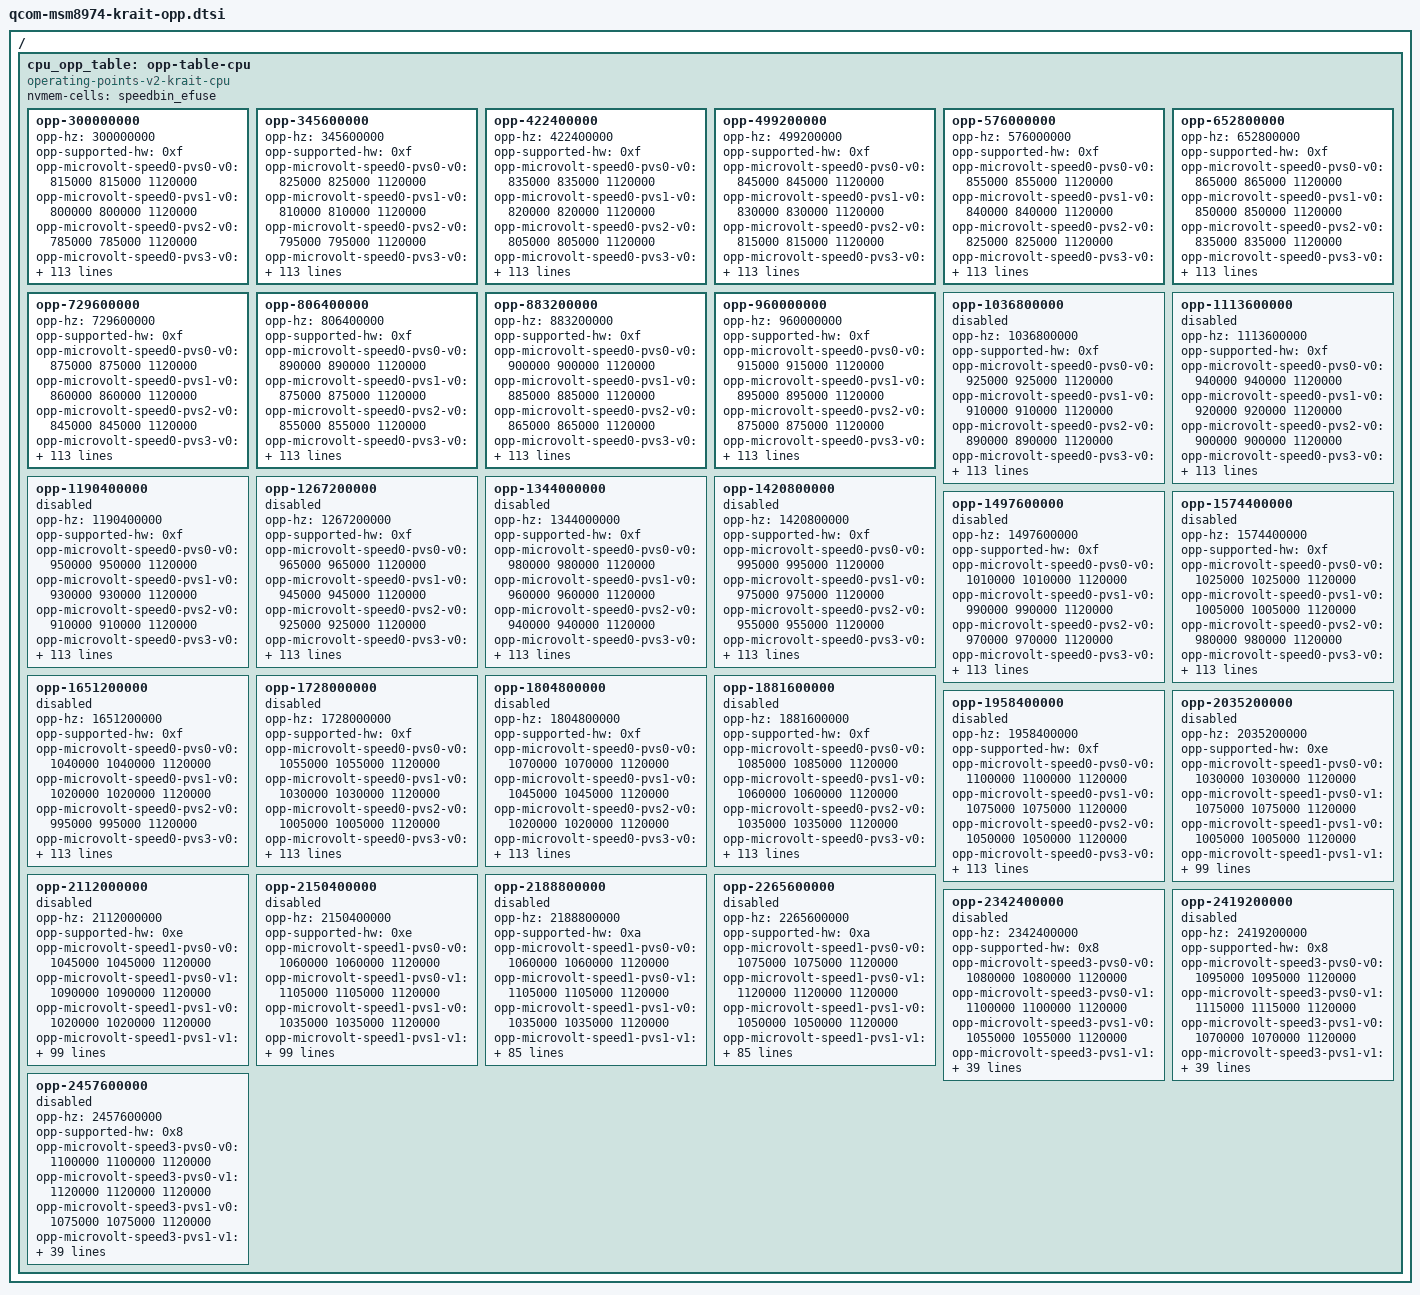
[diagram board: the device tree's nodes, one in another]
// SPDX-License-Identifier: GPL-2.0
/*
 * Krait CPU operating points for MSM8974.
 *
 * GENERATED by cpufreq/gen-krait-opp.py from Sony's stock device tree.
 * Do not edit by hand; regenerate with a different --cap-hz instead.
 *
 * Every OPP above the cap carries status = "disabled" because Linux has
 * no driver for the Krait per-core LDO/BHS regulator and so cannot raise
 * CPU voltage. See cpufreq/README.md.
 */

/ {
	cpu_opp_table: opp-table-cpu {
		compatible = "operating-points-v2-krait-cpu";
		nvmem-cells = <&speedbin_efuse>;

		opp-300000000 {
			opp-hz = /bits/ 64 <300000000>;
			opp-supported-hw = <0xf>;
			opp-microvolt-speed0-pvs0-v0 = <815000 815000 1120000>;
			opp-microvolt-speed0-pvs1-v0 = <800000 800000 1120000>;
			opp-microvolt-speed0-pvs2-v0 = <785000 785000 1120000>;
			opp-microvolt-speed0-pvs3-v0 = <775000 775000 1120000>;
			opp-microvolt-speed0-pvs4-v0 = <775000 775000 1120000>;
			opp-microvolt-speed0-pvs5-v0 = <750000 750000 1120000>;
			opp-microvolt-speed0-pvs6-v0 = <750000 750000 1120000>;
			opp-microvolt-speed1-pvs0-v0 = <775000 775000 1120000>;
			opp-microvolt-speed1-pvs0-v1 = <800000 800000 1120000>;
			opp-microvolt-speed1-pvs1-v0 = <775000 775000 1120000>;
			opp-microvolt-speed1-pvs1-v1 = <800000 800000 1120000>;
			opp-microvolt-speed1-pvs2-v0 = <750000 750000 1120000>;
			opp-microvolt-speed1-pvs2-v1 = <800000 800000 1120000>;
			opp-microvolt-speed1-pvs3-v0 = <750000 750000 1120000>;
			opp-microvolt-speed1-pvs3-v1 = <800000 800000 1120000>;
			opp-microvolt-speed1-pvs4-v0 = <750000 750000 1120000>;
			opp-microvolt-speed1-pvs4-v1 = <800000 800000 1120000>;
			opp-microvolt-speed1-pvs5-v0 = <725000 725000 1120000>;
			opp-microvolt-speed1-pvs5-v1 = <800000 800000 1120000>;
			opp-microvolt-speed1-pvs6-v0 = <725000 725000 1120000>;
			opp-microvolt-speed1-pvs6-v1 = <775000 775000 1120000>;
			opp-microvolt-speed1-pvs7-v1 = <775000 775000 1120000>;
			opp-microvolt-speed1-pvs8-v1 = <775000 775000 1120000>;
			opp-microvolt-speed1-pvs9-v1 = <775000 775000 1120000>;
			opp-microvolt-speed1-pvs10-v1 = <775000 775000 1120000>;
			opp-microvolt-speed1-pvs11-v1 = <775000 775000 1120000>;
			opp-microvolt-speed1-pvs12-v1 = <775000 775000 1120000>;
			opp-microvolt-speed1-pvs13-v1 = <775000 775000 1120000>;
			opp-microvolt-speed1-pvs14-v1 = <750000 750000 1120000>;
			opp-microvolt-speed1-pvs15-v1 = <750000 750000 1120000>;
			opp-microvolt-speed2-pvs0-v0 = <800000 800000 1120000>;
			opp-microvolt-speed2-pvs1-v0 = <800000 800000 1120000>;
			opp-microvolt-speed2-pvs2-v0 = <775000 775000 1120000>;
			opp-microvolt-speed2-pvs3-v0 = <775000 775000 1120000>;
			opp-microvolt-speed2-pvs4-v0 = <775000 775000 1120000>;
			opp-microvolt-speed2-pvs5-v0 = <750000 750000 1120000>;
			opp-microvolt-speed2-pvs6-v0 = <750000 750000 1120000>;
			opp-microvolt-speed3-pvs0-v0 = <800000 800000 1120000>;
			opp-microvolt-speed3-pvs0-v1 = <800000 800000 1120000>;
			opp-microvolt-speed3-pvs1-v0 = <800000 800000 1120000>;
			opp-microvolt-speed3-pvs1-v1 = <800000 800000 1120000>;
			opp-microvolt-speed3-pvs2-v0 = <775000 775000 1120000>;
			opp-microvolt-speed3-pvs2-v1 = <800000 800000 1120000>;
			opp-microvolt-speed3-pvs3-v0 = <775000 775000 1120000>;
			opp-microvolt-speed3-pvs3-v1 = <800000 800000 1120000>;
			opp-microvolt-speed3-pvs4-v0 = <775000 775000 1120000>;
			opp-microvolt-speed3-pvs4-v1 = <800000 800000 1120000>;
			opp-microvolt-speed3-pvs5-v0 = <750000 750000 1120000>;
			opp-microvolt-speed3-pvs5-v1 = <800000 800000 1120000>;
			opp-microvolt-speed3-pvs6-v0 = <750000 750000 1120000>;
			opp-microvolt-speed3-pvs6-v1 = <775000 775000 1120000>;
			opp-microvolt-speed3-pvs7-v1 = <775000 775000 1120000>;
			opp-microvolt-speed3-pvs8-v1 = <775000 775000 1120000>;
			opp-microvolt-speed3-pvs9-v1 = <775000 775000 1120000>;
			opp-microvolt-speed3-pvs10-v1 = <775000 775000 1120000>;
			opp-microvolt-speed3-pvs11-v1 = <775000 775000 1120000>;
			opp-microvolt-speed3-pvs12-v1 = <775000 775000 1120000>;
			opp-microvolt-speed3-pvs13-v1 = <775000 775000 1120000>;
			opp-microvolt-speed3-pvs14-v1 = <750000 750000 1120000>;
			opp-microvolt-speed3-pvs15-v1 = <750000 750000 1120000>;
		};

		opp-345600000 {
			opp-hz = /bits/ 64 <345600000>;
			opp-supported-hw = <0xf>;
			opp-microvolt-speed0-pvs0-v0 = <825000 825000 1120000>;
			opp-microvolt-speed0-pvs1-v0 = <810000 810000 1120000>;
			opp-microvolt-speed0-pvs2-v0 = <795000 795000 1120000>;
			opp-microvolt-speed0-pvs3-v0 = <780000 780000 1120000>;
			opp-microvolt-speed0-pvs4-v0 = <775000 775000 1120000>;
			opp-microvolt-speed0-pvs5-v0 = <760000 760000 1120000>;
			opp-microvolt-speed0-pvs6-v0 = <750000 750000 1120000>;
			opp-microvolt-speed1-pvs0-v0 = <775000 775000 1120000>;
			opp-microvolt-speed1-pvs0-v1 = <810000 810000 1120000>;
			opp-microvolt-speed1-pvs1-v0 = <775000 775000 1120000>;
			opp-microvolt-speed1-pvs1-v1 = <800000 800000 1120000>;
			opp-microvolt-speed1-pvs2-v0 = <750000 750000 1120000>;
			opp-microvolt-speed1-pvs2-v1 = <800000 800000 1120000>;
			opp-microvolt-speed1-pvs3-v0 = <750000 750000 1120000>;
			opp-microvolt-speed1-pvs3-v1 = <800000 800000 1120000>;
			opp-microvolt-speed1-pvs4-v0 = <750000 750000 1120000>;
			opp-microvolt-speed1-pvs4-v1 = <800000 800000 1120000>;
			opp-microvolt-speed1-pvs5-v0 = <725000 725000 1120000>;
			opp-microvolt-speed1-pvs5-v1 = <800000 800000 1120000>;
			opp-microvolt-speed1-pvs6-v0 = <725000 725000 1120000>;
			opp-microvolt-speed1-pvs6-v1 = <775000 775000 1120000>;
			opp-microvolt-speed1-pvs7-v1 = <775000 775000 1120000>;
			opp-microvolt-speed1-pvs8-v1 = <775000 775000 1120000>;
			opp-microvolt-speed1-pvs9-v1 = <775000 775000 1120000>;
			opp-microvolt-speed1-pvs10-v1 = <775000 775000 1120000>;
			opp-microvolt-speed1-pvs11-v1 = <775000 775000 1120000>;
			opp-microvolt-speed1-pvs12-v1 = <775000 775000 1120000>;
			opp-microvolt-speed1-pvs13-v1 = <775000 775000 1120000>;
			opp-microvolt-speed1-pvs14-v1 = <750000 750000 1120000>;
			opp-microvolt-speed1-pvs15-v1 = <750000 750000 1120000>;
			opp-microvolt-speed2-pvs0-v0 = <800000 800000 1120000>;
			opp-microvolt-speed2-pvs1-v0 = <800000 800000 1120000>;
			opp-microvolt-speed2-pvs2-v0 = <775000 775000 1120000>;
			opp-microvolt-speed2-pvs3-v0 = <775000 775000 1120000>;
			opp-microvolt-speed2-pvs4-v0 = <775000 775000 1120000>;
			opp-microvolt-speed2-pvs5-v0 = <750000 750000 1120000>;
			opp-microvolt-speed2-pvs6-v0 = <750000 750000 1120000>;
			opp-microvolt-speed3-pvs0-v0 = <800000 800000 1120000>;
			opp-microvolt-speed3-pvs0-v1 = <800000 800000 1120000>;
			opp-microvolt-speed3-pvs1-v0 = <800000 800000 1120000>;
			opp-microvolt-speed3-pvs1-v1 = <800000 800000 1120000>;
			opp-microvolt-speed3-pvs2-v0 = <775000 775000 1120000>;
			opp-microvolt-speed3-pvs2-v1 = <800000 800000 1120000>;
			opp-microvolt-speed3-pvs3-v0 = <775000 775000 1120000>;
			opp-microvolt-speed3-pvs3-v1 = <800000 800000 1120000>;
			opp-microvolt-speed3-pvs4-v0 = <775000 775000 1120000>;
			opp-microvolt-speed3-pvs4-v1 = <800000 800000 1120000>;
			opp-microvolt-speed3-pvs5-v0 = <750000 750000 1120000>;
			opp-microvolt-speed3-pvs5-v1 = <800000 800000 1120000>;
			opp-microvolt-speed3-pvs6-v0 = <750000 750000 1120000>;
			opp-microvolt-speed3-pvs6-v1 = <775000 775000 1120000>;
			opp-microvolt-speed3-pvs7-v1 = <775000 775000 1120000>;
			opp-microvolt-speed3-pvs8-v1 = <775000 775000 1120000>;
			opp-microvolt-speed3-pvs9-v1 = <775000 775000 1120000>;
			opp-microvolt-speed3-pvs10-v1 = <775000 775000 1120000>;
			opp-microvolt-speed3-pvs11-v1 = <775000 775000 1120000>;
			opp-microvolt-speed3-pvs12-v1 = <775000 775000 1120000>;
			opp-microvolt-speed3-pvs13-v1 = <775000 775000 1120000>;
			opp-microvolt-speed3-pvs14-v1 = <750000 750000 1120000>;
			opp-microvolt-speed3-pvs15-v1 = <750000 750000 1120000>;
		};

		opp-422400000 {
			opp-hz = /bits/ 64 <422400000>;
			opp-supported-hw = <0xf>;
			opp-microvolt-speed0-pvs0-v0 = <835000 835000 1120000>;
			opp-microvolt-speed0-pvs1-v0 = <820000 820000 1120000>;
			opp-microvolt-speed0-pvs2-v0 = <805000 805000 1120000>;
			opp-microvolt-speed0-pvs3-v0 = <790000 790000 1120000>;
			opp-microvolt-speed0-pvs4-v0 = <780000 780000 1120000>;
			opp-microvolt-speed0-pvs5-v0 = <770000 770000 1120000>;
			opp-microvolt-speed0-pvs6-v0 = <760000 760000 1120000>;
			opp-microvolt-speed1-pvs0-v0 = <775000 775000 1120000>;
			opp-microvolt-speed1-pvs0-v1 = <820000 820000 1120000>;
			opp-microvolt-speed1-pvs1-v0 = <775000 775000 1120000>;
			opp-microvolt-speed1-pvs1-v1 = <810000 810000 1120000>;
			opp-microvolt-speed1-pvs2-v0 = <750000 750000 1120000>;
			opp-microvolt-speed1-pvs2-v1 = <800000 800000 1120000>;
			opp-microvolt-speed1-pvs3-v0 = <750000 750000 1120000>;
			opp-microvolt-speed1-pvs3-v1 = <800000 800000 1120000>;
			opp-microvolt-speed1-pvs4-v0 = <750000 750000 1120000>;
			opp-microvolt-speed1-pvs4-v1 = <800000 800000 1120000>;
			opp-microvolt-speed1-pvs5-v0 = <725000 725000 1120000>;
			opp-microvolt-speed1-pvs5-v1 = <800000 800000 1120000>;
			opp-microvolt-speed1-pvs6-v0 = <725000 725000 1120000>;
			opp-microvolt-speed1-pvs6-v1 = <775000 775000 1120000>;
			opp-microvolt-speed1-pvs7-v1 = <775000 775000 1120000>;
			opp-microvolt-speed1-pvs8-v1 = <775000 775000 1120000>;
			opp-microvolt-speed1-pvs9-v1 = <775000 775000 1120000>;
			opp-microvolt-speed1-pvs10-v1 = <775000 775000 1120000>;
			opp-microvolt-speed1-pvs11-v1 = <775000 775000 1120000>;
			opp-microvolt-speed1-pvs12-v1 = <775000 775000 1120000>;
			opp-microvolt-speed1-pvs13-v1 = <775000 775000 1120000>;
			opp-microvolt-speed1-pvs14-v1 = <750000 750000 1120000>;
			opp-microvolt-speed1-pvs15-v1 = <750000 750000 1120000>;
			opp-microvolt-speed2-pvs0-v0 = <805000 805000 1120000>;
			opp-microvolt-speed2-pvs1-v0 = <800000 800000 1120000>;
			opp-microvolt-speed2-pvs2-v0 = <775000 775000 1120000>;
			opp-microvolt-speed2-pvs3-v0 = <775000 775000 1120000>;
			opp-microvolt-speed2-pvs4-v0 = <775000 775000 1120000>;
			opp-microvolt-speed2-pvs5-v0 = <750000 750000 1120000>;
			opp-microvolt-speed2-pvs6-v0 = <750000 750000 1120000>;
			opp-microvolt-speed3-pvs0-v0 = <800000 800000 1120000>;
			opp-microvolt-speed3-pvs0-v1 = <800000 800000 1120000>;
			opp-microvolt-speed3-pvs1-v0 = <800000 800000 1120000>;
			opp-microvolt-speed3-pvs1-v1 = <800000 800000 1120000>;
			opp-microvolt-speed3-pvs2-v0 = <775000 775000 1120000>;
			opp-microvolt-speed3-pvs2-v1 = <800000 800000 1120000>;
			opp-microvolt-speed3-pvs3-v0 = <775000 775000 1120000>;
			opp-microvolt-speed3-pvs3-v1 = <800000 800000 1120000>;
			opp-microvolt-speed3-pvs4-v0 = <775000 775000 1120000>;
			opp-microvolt-speed3-pvs4-v1 = <800000 800000 1120000>;
			opp-microvolt-speed3-pvs5-v0 = <750000 750000 1120000>;
			opp-microvolt-speed3-pvs5-v1 = <800000 800000 1120000>;
			opp-microvolt-speed3-pvs6-v0 = <750000 750000 1120000>;
			opp-microvolt-speed3-pvs6-v1 = <775000 775000 1120000>;
			opp-microvolt-speed3-pvs7-v1 = <775000 775000 1120000>;
			opp-microvolt-speed3-pvs8-v1 = <775000 775000 1120000>;
			opp-microvolt-speed3-pvs9-v1 = <775000 775000 1120000>;
			opp-microvolt-speed3-pvs10-v1 = <775000 775000 1120000>;
			opp-microvolt-speed3-pvs11-v1 = <775000 775000 1120000>;
			opp-microvolt-speed3-pvs12-v1 = <775000 775000 1120000>;
			opp-microvolt-speed3-pvs13-v1 = <775000 775000 1120000>;
			opp-microvolt-speed3-pvs14-v1 = <750000 750000 1120000>;
			opp-microvolt-speed3-pvs15-v1 = <750000 750000 1120000>;
		};

		opp-499200000 {
			opp-hz = /bits/ 64 <499200000>;
			opp-supported-hw = <0xf>;
			opp-microvolt-speed0-pvs0-v0 = <845000 845000 1120000>;
			opp-microvolt-speed0-pvs1-v0 = <830000 830000 1120000>;
			opp-microvolt-speed0-pvs2-v0 = <815000 815000 1120000>;
			opp-microvolt-speed0-pvs3-v0 = <800000 800000 1120000>;
			opp-microvolt-speed0-pvs4-v0 = <790000 790000 1120000>;
			opp-microvolt-speed0-pvs5-v0 = <780000 780000 1120000>;
			opp-microvolt-speed0-pvs6-v0 = <770000 770000 1120000>;
			opp-microvolt-speed1-pvs0-v0 = <780000 780000 1120000>;
			opp-microvolt-speed1-pvs0-v1 = <830000 830000 1120000>;
			opp-microvolt-speed1-pvs1-v0 = <775000 775000 1120000>;
			opp-microvolt-speed1-pvs1-v1 = <820000 820000 1120000>;
			opp-microvolt-speed1-pvs2-v0 = <750000 750000 1120000>;
			opp-microvolt-speed1-pvs2-v1 = <810000 810000 1120000>;
			opp-microvolt-speed1-pvs3-v0 = <750000 750000 1120000>;
			opp-microvolt-speed1-pvs3-v1 = <800000 800000 1120000>;
			opp-microvolt-speed1-pvs4-v0 = <750000 750000 1120000>;
			opp-microvolt-speed1-pvs4-v1 = <800000 800000 1120000>;
			opp-microvolt-speed1-pvs5-v0 = <725000 725000 1120000>;
			opp-microvolt-speed1-pvs5-v1 = <800000 800000 1120000>;
			opp-microvolt-speed1-pvs6-v0 = <725000 725000 1120000>;
			opp-microvolt-speed1-pvs6-v1 = <775000 775000 1120000>;
			opp-microvolt-speed1-pvs7-v1 = <775000 775000 1120000>;
			opp-microvolt-speed1-pvs8-v1 = <775000 775000 1120000>;
			opp-microvolt-speed1-pvs9-v1 = <775000 775000 1120000>;
			opp-microvolt-speed1-pvs10-v1 = <775000 775000 1120000>;
			opp-microvolt-speed1-pvs11-v1 = <775000 775000 1120000>;
			opp-microvolt-speed1-pvs12-v1 = <775000 775000 1120000>;
			opp-microvolt-speed1-pvs13-v1 = <775000 775000 1120000>;
			opp-microvolt-speed1-pvs14-v1 = <750000 750000 1120000>;
			opp-microvolt-speed1-pvs15-v1 = <750000 750000 1120000>;
			opp-microvolt-speed2-pvs0-v0 = <815000 815000 1120000>;
			opp-microvolt-speed2-pvs1-v0 = <800000 800000 1120000>;
			opp-microvolt-speed2-pvs2-v0 = <785000 785000 1120000>;
			opp-microvolt-speed2-pvs3-v0 = <775000 775000 1120000>;
			opp-microvolt-speed2-pvs4-v0 = <775000 775000 1120000>;
			opp-microvolt-speed2-pvs5-v0 = <750000 750000 1120000>;
			opp-microvolt-speed2-pvs6-v0 = <750000 750000 1120000>;
			opp-microvolt-speed3-pvs0-v0 = <800000 800000 1120000>;
			opp-microvolt-speed3-pvs0-v1 = <810000 810000 1120000>;
			opp-microvolt-speed3-pvs1-v0 = <800000 800000 1120000>;
			opp-microvolt-speed3-pvs1-v1 = <800000 800000 1120000>;
			opp-microvolt-speed3-pvs2-v0 = <775000 775000 1120000>;
			opp-microvolt-speed3-pvs2-v1 = <800000 800000 1120000>;
			opp-microvolt-speed3-pvs3-v0 = <775000 775000 1120000>;
			opp-microvolt-speed3-pvs3-v1 = <800000 800000 1120000>;
			opp-microvolt-speed3-pvs4-v0 = <775000 775000 1120000>;
			opp-microvolt-speed3-pvs4-v1 = <800000 800000 1120000>;
			opp-microvolt-speed3-pvs5-v0 = <750000 750000 1120000>;
			opp-microvolt-speed3-pvs5-v1 = <800000 800000 1120000>;
			opp-microvolt-speed3-pvs6-v0 = <750000 750000 1120000>;
			opp-microvolt-speed3-pvs6-v1 = <775000 775000 1120000>;
			opp-microvolt-speed3-pvs7-v1 = <775000 775000 1120000>;
			opp-microvolt-speed3-pvs8-v1 = <775000 775000 1120000>;
			opp-microvolt-speed3-pvs9-v1 = <775000 775000 1120000>;
			opp-microvolt-speed3-pvs10-v1 = <775000 775000 1120000>;
			opp-microvolt-speed3-pvs11-v1 = <775000 775000 1120000>;
			opp-microvolt-speed3-pvs12-v1 = <775000 775000 1120000>;
			opp-microvolt-speed3-pvs13-v1 = <775000 775000 1120000>;
			opp-microvolt-speed3-pvs14-v1 = <750000 750000 1120000>;
			opp-microvolt-speed3-pvs15-v1 = <750000 750000 1120000>;
		};

		opp-576000000 {
			opp-hz = /bits/ 64 <576000000>;
			opp-supported-hw = <0xf>;
			opp-microvolt-speed0-pvs0-v0 = <855000 855000 1120000>;
			opp-microvolt-speed0-pvs1-v0 = <840000 840000 1120000>;
			opp-microvolt-speed0-pvs2-v0 = <825000 825000 1120000>;
			opp-microvolt-speed0-pvs3-v0 = <810000 810000 1120000>;
			opp-microvolt-speed0-pvs4-v0 = <800000 800000 1120000>;
			opp-microvolt-speed0-pvs5-v0 = <790000 790000 1120000>;
			opp-microvolt-speed0-pvs6-v0 = <780000 780000 1120000>;
			opp-microvolt-speed1-pvs0-v0 = <790000 790000 1120000>;
			opp-microvolt-speed1-pvs0-v1 = <840000 840000 1120000>;
			opp-microvolt-speed1-pvs1-v0 = <775000 775000 1120000>;
			opp-microvolt-speed1-pvs1-v1 = <830000 830000 1120000>;
			opp-microvolt-speed1-pvs2-v0 = <760000 760000 1120000>;
			opp-microvolt-speed1-pvs2-v1 = <820000 820000 1120000>;
			opp-microvolt-speed1-pvs3-v0 = <750000 750000 1120000>;
			opp-microvolt-speed1-pvs3-v1 = <810000 810000 1120000>;
			opp-microvolt-speed1-pvs4-v0 = <750000 750000 1120000>;
			opp-microvolt-speed1-pvs4-v1 = <800000 800000 1120000>;
			opp-microvolt-speed1-pvs5-v0 = <725000 725000 1120000>;
			opp-microvolt-speed1-pvs5-v1 = <800000 800000 1120000>;
			opp-microvolt-speed1-pvs6-v0 = <725000 725000 1120000>;
			opp-microvolt-speed1-pvs6-v1 = <785000 785000 1120000>;
			opp-microvolt-speed1-pvs7-v1 = <780000 780000 1120000>;
			opp-microvolt-speed1-pvs8-v1 = <775000 775000 1120000>;
			opp-microvolt-speed1-pvs9-v1 = <775000 775000 1120000>;
			opp-microvolt-speed1-pvs10-v1 = <775000 775000 1120000>;
			opp-microvolt-speed1-pvs11-v1 = <775000 775000 1120000>;
			opp-microvolt-speed1-pvs12-v1 = <775000 775000 1120000>;
			opp-microvolt-speed1-pvs13-v1 = <775000 775000 1120000>;
			opp-microvolt-speed1-pvs14-v1 = <750000 750000 1120000>;
			opp-microvolt-speed1-pvs15-v1 = <750000 750000 1120000>;
			opp-microvolt-speed2-pvs0-v0 = <825000 825000 1120000>;
			opp-microvolt-speed2-pvs1-v0 = <810000 810000 1120000>;
			opp-microvolt-speed2-pvs2-v0 = <795000 795000 1120000>;
			opp-microvolt-speed2-pvs3-v0 = <780000 780000 1120000>;
			opp-microvolt-speed2-pvs4-v0 = <775000 775000 1120000>;
			opp-microvolt-speed2-pvs5-v0 = <760000 760000 1120000>;
			opp-microvolt-speed2-pvs6-v0 = <750000 750000 1120000>;
			opp-microvolt-speed3-pvs0-v0 = <800000 800000 1120000>;
			opp-microvolt-speed3-pvs0-v1 = <820000 820000 1120000>;
			opp-microvolt-speed3-pvs1-v0 = <800000 800000 1120000>;
			opp-microvolt-speed3-pvs1-v1 = <810000 810000 1120000>;
			opp-microvolt-speed3-pvs2-v0 = <775000 775000 1120000>;
			opp-microvolt-speed3-pvs2-v1 = <800000 800000 1120000>;
			opp-microvolt-speed3-pvs3-v0 = <775000 775000 1120000>;
			opp-microvolt-speed3-pvs3-v1 = <800000 800000 1120000>;
			opp-microvolt-speed3-pvs4-v0 = <775000 775000 1120000>;
			opp-microvolt-speed3-pvs4-v1 = <800000 800000 1120000>;
			opp-microvolt-speed3-pvs5-v0 = <750000 750000 1120000>;
			opp-microvolt-speed3-pvs5-v1 = <800000 800000 1120000>;
			opp-microvolt-speed3-pvs6-v0 = <750000 750000 1120000>;
			opp-microvolt-speed3-pvs6-v1 = <775000 775000 1120000>;
			opp-microvolt-speed3-pvs7-v1 = <775000 775000 1120000>;
			opp-microvolt-speed3-pvs8-v1 = <775000 775000 1120000>;
			opp-microvolt-speed3-pvs9-v1 = <775000 775000 1120000>;
			opp-microvolt-speed3-pvs10-v1 = <775000 775000 1120000>;
			opp-microvolt-speed3-pvs11-v1 = <775000 775000 1120000>;
			opp-microvolt-speed3-pvs12-v1 = <775000 775000 1120000>;
			opp-microvolt-speed3-pvs13-v1 = <775000 775000 1120000>;
			opp-microvolt-speed3-pvs14-v1 = <750000 750000 1120000>;
			opp-microvolt-speed3-pvs15-v1 = <750000 750000 1120000>;
		};

		opp-652800000 {
			opp-hz = /bits/ 64 <652800000>;
			opp-supported-hw = <0xf>;
			opp-microvolt-speed0-pvs0-v0 = <865000 865000 1120000>;
			opp-microvolt-speed0-pvs1-v0 = <850000 850000 1120000>;
			opp-microvolt-speed0-pvs2-v0 = <835000 835000 1120000>;
			opp-microvolt-speed0-pvs3-v0 = <820000 820000 1120000>;
			opp-microvolt-speed0-pvs4-v0 = <810000 810000 1120000>;
			opp-microvolt-speed0-pvs5-v0 = <800000 800000 1120000>;
			opp-microvolt-speed0-pvs6-v0 = <790000 790000 1120000>;
			opp-microvolt-speed1-pvs0-v0 = <800000 800000 1120000>;
			opp-microvolt-speed1-pvs0-v1 = <850000 850000 1120000>;
			opp-microvolt-speed1-pvs1-v0 = <785000 785000 1120000>;
			opp-microvolt-speed1-pvs1-v1 = <840000 840000 1120000>;
			opp-microvolt-speed1-pvs2-v0 = <770000 770000 1120000>;
			opp-microvolt-speed1-pvs2-v1 = <830000 830000 1120000>;
			opp-microvolt-speed1-pvs3-v0 = <755000 755000 1120000>;
			opp-microvolt-speed1-pvs3-v1 = <820000 820000 1120000>;
			opp-microvolt-speed1-pvs4-v0 = <750000 750000 1120000>;
			opp-microvolt-speed1-pvs4-v1 = <810000 810000 1120000>;
			opp-microvolt-speed1-pvs5-v0 = <735000 735000 1120000>;
			opp-microvolt-speed1-pvs5-v1 = <800000 800000 1120000>;
			opp-microvolt-speed1-pvs6-v0 = <725000 725000 1120000>;
			opp-microvolt-speed1-pvs6-v1 = <795000 795000 1120000>;
			opp-microvolt-speed1-pvs7-v1 = <790000 790000 1120000>;
			opp-microvolt-speed1-pvs8-v1 = <780000 780000 1120000>;
			opp-microvolt-speed1-pvs9-v1 = <775000 775000 1120000>;
			opp-microvolt-speed1-pvs10-v1 = <775000 775000 1120000>;
			opp-microvolt-speed1-pvs11-v1 = <775000 775000 1120000>;
			opp-microvolt-speed1-pvs12-v1 = <775000 775000 1120000>;
			opp-microvolt-speed1-pvs13-v1 = <775000 775000 1120000>;
			opp-microvolt-speed1-pvs14-v1 = <750000 750000 1120000>;
			opp-microvolt-speed1-pvs15-v1 = <750000 750000 1120000>;
			opp-microvolt-speed2-pvs0-v0 = <835000 835000 1120000>;
			opp-microvolt-speed2-pvs1-v0 = <820000 820000 1120000>;
			opp-microvolt-speed2-pvs2-v0 = <805000 805000 1120000>;
			opp-microvolt-speed2-pvs3-v0 = <790000 790000 1120000>;
			opp-microvolt-speed2-pvs4-v0 = <780000 780000 1120000>;
			opp-microvolt-speed2-pvs5-v0 = <770000 770000 1120000>;
			opp-microvolt-speed2-pvs6-v0 = <760000 760000 1120000>;
			opp-microvolt-speed3-pvs0-v0 = <810000 810000 1120000>;
			opp-microvolt-speed3-pvs0-v1 = <830000 830000 1120000>;
			opp-microvolt-speed3-pvs1-v0 = <800000 800000 1120000>;
			opp-microvolt-speed3-pvs1-v1 = <820000 820000 1120000>;
			opp-microvolt-speed3-pvs2-v0 = <775000 775000 1120000>;
			opp-microvolt-speed3-pvs2-v1 = <810000 810000 1120000>;
			opp-microvolt-speed3-pvs3-v0 = <775000 775000 1120000>;
			opp-microvolt-speed3-pvs3-v1 = <800000 800000 1120000>;
			opp-microvolt-speed3-pvs4-v0 = <775000 775000 1120000>;
			opp-microvolt-speed3-pvs4-v1 = <800000 800000 1120000>;
			opp-microvolt-speed3-pvs5-v0 = <750000 750000 1120000>;
			opp-microvolt-speed3-pvs5-v1 = <800000 800000 1120000>;
			opp-microvolt-speed3-pvs6-v0 = <750000 750000 1120000>;
			opp-microvolt-speed3-pvs6-v1 = <775000 775000 1120000>;
			opp-microvolt-speed3-pvs7-v1 = <775000 775000 1120000>;
			opp-microvolt-speed3-pvs8-v1 = <775000 775000 1120000>;
			opp-microvolt-speed3-pvs9-v1 = <775000 775000 1120000>;
			opp-microvolt-speed3-pvs10-v1 = <775000 775000 1120000>;
			opp-microvolt-speed3-pvs11-v1 = <775000 775000 1120000>;
			opp-microvolt-speed3-pvs12-v1 = <775000 775000 1120000>;
			opp-microvolt-speed3-pvs13-v1 = <775000 775000 1120000>;
			opp-microvolt-speed3-pvs14-v1 = <750000 750000 1120000>;
			opp-microvolt-speed3-pvs15-v1 = <750000 750000 1120000>;
		};

		opp-729600000 {
			opp-hz = /bits/ 64 <729600000>;
			opp-supported-hw = <0xf>;
			opp-microvolt-speed0-pvs0-v0 = <875000 875000 1120000>;
			opp-microvolt-speed0-pvs1-v0 = <860000 860000 1120000>;
			opp-microvolt-speed0-pvs2-v0 = <845000 845000 1120000>;
			opp-microvolt-speed0-pvs3-v0 = <830000 830000 1120000>;
			opp-microvolt-speed0-pvs4-v0 = <820000 820000 1120000>;
			opp-microvolt-speed0-pvs5-v0 = <810000 810000 1120000>;
			opp-microvolt-speed0-pvs6-v0 = <800000 800000 1120000>;
			opp-microvolt-speed1-pvs0-v0 = <810000 810000 1120000>;
			opp-microvolt-speed1-pvs0-v1 = <860000 860000 1120000>;
			opp-microvolt-speed1-pvs1-v0 = <795000 795000 1120000>;
			opp-microvolt-speed1-pvs1-v1 = <850000 850000 1120000>;
			opp-microvolt-speed1-pvs2-v0 = <780000 780000 1120000>;
			opp-microvolt-speed1-pvs2-v1 = <840000 840000 1120000>;
			opp-microvolt-speed1-pvs3-v0 = <765000 765000 1120000>;
			opp-microvolt-speed1-pvs3-v1 = <830000 830000 1120000>;
			opp-microvolt-speed1-pvs4-v0 = <755000 755000 1120000>;
			opp-microvolt-speed1-pvs4-v1 = <820000 820000 1120000>;
			opp-microvolt-speed1-pvs5-v0 = <745000 745000 1120000>;
			opp-microvolt-speed1-pvs5-v1 = <810000 810000 1120000>;
			opp-microvolt-speed1-pvs6-v0 = <735000 735000 1120000>;
			opp-microvolt-speed1-pvs6-v1 = <805000 805000 1120000>;
			opp-microvolt-speed1-pvs7-v1 = <800000 800000 1120000>;
			opp-microvolt-speed1-pvs8-v1 = <790000 790000 1120000>;
			opp-microvolt-speed1-pvs9-v1 = <785000 785000 1120000>;
			opp-microvolt-speed1-pvs10-v1 = <780000 780000 1120000>;
			opp-microvolt-speed1-pvs11-v1 = <775000 775000 1120000>;
			opp-microvolt-speed1-pvs12-v1 = <775000 775000 1120000>;
			opp-microvolt-speed1-pvs13-v1 = <775000 775000 1120000>;
			opp-microvolt-speed1-pvs14-v1 = <760000 760000 1120000>;
			opp-microvolt-speed1-pvs15-v1 = <755000 755000 1120000>;
			opp-microvolt-speed2-pvs0-v0 = <845000 845000 1120000>;
			opp-microvolt-speed2-pvs1-v0 = <830000 830000 1120000>;
			opp-microvolt-speed2-pvs2-v0 = <815000 815000 1120000>;
			opp-microvolt-speed2-pvs3-v0 = <800000 800000 1120000>;
			opp-microvolt-speed2-pvs4-v0 = <790000 790000 1120000>;
			opp-microvolt-speed2-pvs5-v0 = <780000 780000 1120000>;
			opp-microvolt-speed2-pvs6-v0 = <770000 770000 1120000>;
			opp-microvolt-speed3-pvs0-v0 = <820000 820000 1120000>;
			opp-microvolt-speed3-pvs0-v1 = <840000 840000 1120000>;
			opp-microvolt-speed3-pvs1-v0 = <800000 800000 1120000>;
			opp-microvolt-speed3-pvs1-v1 = <830000 830000 1120000>;
			opp-microvolt-speed3-pvs2-v0 = <775000 775000 1120000>;
			opp-microvolt-speed3-pvs2-v1 = <820000 820000 1120000>;
			opp-microvolt-speed3-pvs3-v0 = <775000 775000 1120000>;
			opp-microvolt-speed3-pvs3-v1 = <810000 810000 1120000>;
			opp-microvolt-speed3-pvs4-v0 = <775000 775000 1120000>;
			opp-microvolt-speed3-pvs4-v1 = <800000 800000 1120000>;
			opp-microvolt-speed3-pvs5-v0 = <750000 750000 1120000>;
			opp-microvolt-speed3-pvs5-v1 = <800000 800000 1120000>;
			opp-microvolt-speed3-pvs6-v0 = <750000 750000 1120000>;
			opp-microvolt-speed3-pvs6-v1 = <780000 780000 1120000>;
			opp-microvolt-speed3-pvs7-v1 = <780000 780000 1120000>;
			opp-microvolt-speed3-pvs8-v1 = <775000 775000 1120000>;
			opp-microvolt-speed3-pvs9-v1 = <775000 775000 1120000>;
			opp-microvolt-speed3-pvs10-v1 = <775000 775000 1120000>;
			opp-microvolt-speed3-pvs11-v1 = <775000 775000 1120000>;
			opp-microvolt-speed3-pvs12-v1 = <775000 775000 1120000>;
			opp-microvolt-speed3-pvs13-v1 = <775000 775000 1120000>;
			opp-microvolt-speed3-pvs14-v1 = <750000 750000 1120000>;
			opp-microvolt-speed3-pvs15-v1 = <750000 750000 1120000>;
		};

		opp-806400000 {
			opp-hz = /bits/ 64 <806400000>;
			opp-supported-hw = <0xf>;
			opp-microvolt-speed0-pvs0-v0 = <890000 890000 1120000>;
			opp-microvolt-speed0-pvs1-v0 = <875000 875000 1120000>;
			opp-microvolt-speed0-pvs2-v0 = <855000 855000 1120000>;
			opp-microvolt-speed0-pvs3-v0 = <840000 840000 1120000>;
			opp-microvolt-speed0-pvs4-v0 = <830000 830000 1120000>;
			opp-microvolt-speed0-pvs5-v0 = <820000 820000 1120000>;
			opp-microvolt-speed0-pvs6-v0 = <810000 810000 1120000>;
			opp-microvolt-speed1-pvs0-v0 = <820000 820000 1120000>;
			opp-microvolt-speed1-pvs0-v1 = <870000 870000 1120000>;
			opp-microvolt-speed1-pvs1-v0 = <805000 805000 1120000>;
			opp-microvolt-speed1-pvs1-v1 = <860000 860000 1120000>;
			opp-microvolt-speed1-pvs2-v0 = <790000 790000 1120000>;
			opp-microvolt-speed1-pvs2-v1 = <850000 850000 1120000>;
			opp-microvolt-speed1-pvs3-v0 = <775000 775000 1120000>;
			opp-microvolt-speed1-pvs3-v1 = <840000 840000 1120000>;
			opp-microvolt-speed1-pvs4-v0 = <765000 765000 1120000>;
			opp-microvolt-speed1-pvs4-v1 = <830000 830000 1120000>;
			opp-microvolt-speed1-pvs5-v0 = <755000 755000 1120000>;
			opp-microvolt-speed1-pvs5-v1 = <820000 820000 1120000>;
			opp-microvolt-speed1-pvs6-v0 = <745000 745000 1120000>;
			opp-microvolt-speed1-pvs6-v1 = <815000 815000 1120000>;
			opp-microvolt-speed1-pvs7-v1 = <810000 810000 1120000>;
			opp-microvolt-speed1-pvs8-v1 = <800000 800000 1120000>;
			opp-microvolt-speed1-pvs9-v1 = <795000 795000 1120000>;
			opp-microvolt-speed1-pvs10-v1 = <790000 790000 1120000>;
			opp-microvolt-speed1-pvs11-v1 = <785000 785000 1120000>;
			opp-microvolt-speed1-pvs12-v1 = <780000 780000 1120000>;
			opp-microvolt-speed1-pvs13-v1 = <775000 775000 1120000>;
			opp-microvolt-speed1-pvs14-v1 = <770000 770000 1120000>;
			opp-microvolt-speed1-pvs15-v1 = <765000 765000 1120000>;
			opp-microvolt-speed2-pvs0-v0 = <855000 855000 1120000>;
			opp-microvolt-speed2-pvs1-v0 = <840000 840000 1120000>;
			opp-microvolt-speed2-pvs2-v0 = <825000 825000 1120000>;
			opp-microvolt-speed2-pvs3-v0 = <810000 810000 1120000>;
			opp-microvolt-speed2-pvs4-v0 = <800000 800000 1120000>;
			opp-microvolt-speed2-pvs5-v0 = <790000 790000 1120000>;
			opp-microvolt-speed2-pvs6-v0 = <780000 780000 1120000>;
			opp-microvolt-speed3-pvs0-v0 = <830000 830000 1120000>;
			opp-microvolt-speed3-pvs0-v1 = <850000 850000 1120000>;
			opp-microvolt-speed3-pvs1-v0 = <805000 805000 1120000>;
			opp-microvolt-speed3-pvs1-v1 = <840000 840000 1120000>;
			opp-microvolt-speed3-pvs2-v0 = <780000 780000 1120000>;
			opp-microvolt-speed3-pvs2-v1 = <830000 830000 1120000>;
			opp-microvolt-speed3-pvs3-v0 = <775000 775000 1120000>;
			opp-microvolt-speed3-pvs3-v1 = <820000 820000 1120000>;
			opp-microvolt-speed3-pvs4-v0 = <775000 775000 1120000>;
			opp-microvolt-speed3-pvs4-v1 = <810000 810000 1120000>;
			opp-microvolt-speed3-pvs5-v0 = <750000 750000 1120000>;
			opp-microvolt-speed3-pvs5-v1 = <800000 800000 1120000>;
			opp-microvolt-speed3-pvs6-v0 = <750000 750000 1120000>;
			opp-microvolt-speed3-pvs6-v1 = <790000 790000 1120000>;
			opp-microvolt-speed3-pvs7-v1 = <785000 785000 1120000>;
			opp-microvolt-speed3-pvs8-v1 = <780000 780000 1120000>;
			opp-microvolt-speed3-pvs9-v1 = <775000 775000 1120000>;
			opp-microvolt-speed3-pvs10-v1 = <775000 775000 1120000>;
			opp-microvolt-speed3-pvs11-v1 = <775000 775000 1120000>;
			opp-microvolt-speed3-pvs12-v1 = <775000 775000 1120000>;
			opp-microvolt-speed3-pvs13-v1 = <775000 775000 1120000>;
			opp-microvolt-speed3-pvs14-v1 = <750000 750000 1120000>;
			opp-microvolt-speed3-pvs15-v1 = <750000 750000 1120000>;
		};

		opp-883200000 {
			opp-hz = /bits/ 64 <883200000>;
			opp-supported-hw = <0xf>;
			opp-microvolt-speed0-pvs0-v0 = <900000 900000 1120000>;
			opp-microvolt-speed0-pvs1-v0 = <885000 885000 1120000>;
			opp-microvolt-speed0-pvs2-v0 = <865000 865000 1120000>;
			opp-microvolt-speed0-pvs3-v0 = <850000 850000 1120000>;
			opp-microvolt-speed0-pvs4-v0 = <840000 840000 1120000>;
			opp-microvolt-speed0-pvs5-v0 = <830000 830000 1120000>;
			opp-microvolt-speed0-pvs6-v0 = <820000 820000 1120000>;
			opp-microvolt-speed1-pvs0-v0 = <830000 830000 1120000>;
			opp-microvolt-speed1-pvs0-v1 = <880000 880000 1120000>;
			opp-microvolt-speed1-pvs1-v0 = <815000 815000 1120000>;
			opp-microvolt-speed1-pvs1-v1 = <870000 870000 1120000>;
			opp-microvolt-speed1-pvs2-v0 = <800000 800000 1120000>;
			opp-microvolt-speed1-pvs2-v1 = <860000 860000 1120000>;
			opp-microvolt-speed1-pvs3-v0 = <785000 785000 1120000>;
			opp-microvolt-speed1-pvs3-v1 = <850000 850000 1120000>;
			opp-microvolt-speed1-pvs4-v0 = <775000 775000 1120000>;
			opp-microvolt-speed1-pvs4-v1 = <840000 840000 1120000>;
			opp-microvolt-speed1-pvs5-v0 = <765000 765000 1120000>;
			opp-microvolt-speed1-pvs5-v1 = <830000 830000 1120000>;
			opp-microvolt-speed1-pvs6-v0 = <755000 755000 1120000>;
			opp-microvolt-speed1-pvs6-v1 = <825000 825000 1120000>;
			opp-microvolt-speed1-pvs7-v1 = <820000 820000 1120000>;
			opp-microvolt-speed1-pvs8-v1 = <810000 810000 1120000>;
			opp-microvolt-speed1-pvs9-v1 = <805000 805000 1120000>;
			opp-microvolt-speed1-pvs10-v1 = <800000 800000 1120000>;
			opp-microvolt-speed1-pvs11-v1 = <795000 795000 1120000>;
			opp-microvolt-speed1-pvs12-v1 = <790000 790000 1120000>;
			opp-microvolt-speed1-pvs13-v1 = <785000 785000 1120000>;
			opp-microvolt-speed1-pvs14-v1 = <780000 780000 1120000>;
			opp-microvolt-speed1-pvs15-v1 = <775000 775000 1120000>;
			opp-microvolt-speed2-pvs0-v0 = <865000 865000 1120000>;
			opp-microvolt-speed2-pvs1-v0 = <850000 850000 1120000>;
			opp-microvolt-speed2-pvs2-v0 = <835000 835000 1120000>;
			opp-microvolt-speed2-pvs3-v0 = <820000 820000 1120000>;
			opp-microvolt-speed2-pvs4-v0 = <810000 810000 1120000>;
			opp-microvolt-speed2-pvs5-v0 = <800000 800000 1120000>;
			opp-microvolt-speed2-pvs6-v0 = <790000 790000 1120000>;
			opp-microvolt-speed3-pvs0-v0 = <840000 840000 1120000>;
			opp-microvolt-speed3-pvs0-v1 = <860000 860000 1120000>;
			opp-microvolt-speed3-pvs1-v0 = <815000 815000 1120000>;
			opp-microvolt-speed3-pvs1-v1 = <850000 850000 1120000>;
			opp-microvolt-speed3-pvs2-v0 = <790000 790000 1120000>;
			opp-microvolt-speed3-pvs2-v1 = <840000 840000 1120000>;
			opp-microvolt-speed3-pvs3-v0 = <775000 775000 1120000>;
			opp-microvolt-speed3-pvs3-v1 = <830000 830000 1120000>;
			opp-microvolt-speed3-pvs4-v0 = <775000 775000 1120000>;
			opp-microvolt-speed3-pvs4-v1 = <820000 820000 1120000>;
			opp-microvolt-speed3-pvs5-v0 = <750000 750000 1120000>;
			opp-microvolt-speed3-pvs5-v1 = <810000 810000 1120000>;
			opp-microvolt-speed3-pvs6-v0 = <750000 750000 1120000>;
			opp-microvolt-speed3-pvs6-v1 = <800000 800000 1120000>;
			opp-microvolt-speed3-pvs7-v1 = <795000 795000 1120000>;
			opp-microvolt-speed3-pvs8-v1 = <785000 785000 1120000>;
			opp-microvolt-speed3-pvs9-v1 = <780000 780000 1120000>;
			opp-microvolt-speed3-pvs10-v1 = <780000 780000 1120000>;
			opp-microvolt-speed3-pvs11-v1 = <775000 775000 1120000>;
			opp-microvolt-speed3-pvs12-v1 = <775000 775000 1120000>;
			opp-microvolt-speed3-pvs13-v1 = <775000 775000 1120000>;
			opp-microvolt-speed3-pvs14-v1 = <755000 755000 1120000>;
			opp-microvolt-speed3-pvs15-v1 = <755000 755000 1120000>;
		};

		opp-960000000 {
			opp-hz = /bits/ 64 <960000000>;
			opp-supported-hw = <0xf>;
			opp-microvolt-speed0-pvs0-v0 = <915000 915000 1120000>;
			opp-microvolt-speed0-pvs1-v0 = <895000 895000 1120000>;
			opp-microvolt-speed0-pvs2-v0 = <875000 875000 1120000>;
			opp-microvolt-speed0-pvs3-v0 = <860000 860000 1120000>;
			opp-microvolt-speed0-pvs4-v0 = <850000 850000 1120000>;
			opp-microvolt-speed0-pvs5-v0 = <840000 840000 1120000>;
			opp-microvolt-speed0-pvs6-v0 = <830000 830000 1120000>;
			opp-microvolt-speed1-pvs0-v0 = <840000 840000 1120000>;
			opp-microvolt-speed1-pvs0-v1 = <890000 890000 1120000>;
			opp-microvolt-speed1-pvs1-v0 = <825000 825000 1120000>;
			opp-microvolt-speed1-pvs1-v1 = <880000 880000 1120000>;
			opp-microvolt-speed1-pvs2-v0 = <810000 810000 1120000>;
			opp-microvolt-speed1-pvs2-v1 = <870000 870000 1120000>;
			opp-microvolt-speed1-pvs3-v0 = <795000 795000 1120000>;
			opp-microvolt-speed1-pvs3-v1 = <860000 860000 1120000>;
			opp-microvolt-speed1-pvs4-v0 = <785000 785000 1120000>;
			opp-microvolt-speed1-pvs4-v1 = <850000 850000 1120000>;
			opp-microvolt-speed1-pvs5-v0 = <775000 775000 1120000>;
			opp-microvolt-speed1-pvs5-v1 = <840000 840000 1120000>;
			opp-microvolt-speed1-pvs6-v0 = <765000 765000 1120000>;
			opp-microvolt-speed1-pvs6-v1 = <835000 835000 1120000>;
			opp-microvolt-speed1-pvs7-v1 = <830000 830000 1120000>;
			opp-microvolt-speed1-pvs8-v1 = <820000 820000 1120000>;
			opp-microvolt-speed1-pvs9-v1 = <815000 815000 1120000>;
			opp-microvolt-speed1-pvs10-v1 = <810000 810000 1120000>;
			opp-microvolt-speed1-pvs11-v1 = <805000 805000 1120000>;
			opp-microvolt-speed1-pvs12-v1 = <800000 800000 1120000>;
			opp-microvolt-speed1-pvs13-v1 = <795000 795000 1120000>;
			opp-microvolt-speed1-pvs14-v1 = <790000 790000 1120000>;
			opp-microvolt-speed1-pvs15-v1 = <785000 785000 1120000>;
			opp-microvolt-speed2-pvs0-v0 = <875000 875000 1120000>;
			opp-microvolt-speed2-pvs1-v0 = <860000 860000 1120000>;
			opp-microvolt-speed2-pvs2-v0 = <845000 845000 1120000>;
			opp-microvolt-speed2-pvs3-v0 = <830000 830000 1120000>;
			opp-microvolt-speed2-pvs4-v0 = <820000 820000 1120000>;
			opp-microvolt-speed2-pvs5-v0 = <810000 810000 1120000>;
			opp-microvolt-speed2-pvs6-v0 = <800000 800000 1120000>;
			opp-microvolt-speed3-pvs0-v0 = <850000 850000 1120000>;
			opp-microvolt-speed3-pvs0-v1 = <870000 870000 1120000>;
			opp-microvolt-speed3-pvs1-v0 = <825000 825000 1120000>;
			opp-microvolt-speed3-pvs1-v1 = <860000 860000 1120000>;
			opp-microvolt-speed3-pvs2-v0 = <800000 800000 1120000>;
			opp-microvolt-speed3-pvs2-v1 = <850000 850000 1120000>;
			opp-microvolt-speed3-pvs3-v0 = <780000 780000 1120000>;
			opp-microvolt-speed3-pvs3-v1 = <840000 840000 1120000>;
			opp-microvolt-speed3-pvs4-v0 = <775000 775000 1120000>;
			opp-microvolt-speed3-pvs4-v1 = <830000 830000 1120000>;
			opp-microvolt-speed3-pvs5-v0 = <750000 750000 1120000>;
			opp-microvolt-speed3-pvs5-v1 = <820000 820000 1120000>;
			opp-microvolt-speed3-pvs6-v0 = <750000 750000 1120000>;
			opp-microvolt-speed3-pvs6-v1 = <810000 810000 1120000>;
			opp-microvolt-speed3-pvs7-v1 = <805000 805000 1120000>;
			opp-microvolt-speed3-pvs8-v1 = <795000 795000 1120000>;
			opp-microvolt-speed3-pvs9-v1 = <790000 790000 1120000>;
			opp-microvolt-speed3-pvs10-v1 = <785000 785000 1120000>;
			opp-microvolt-speed3-pvs11-v1 = <780000 780000 1120000>;
			opp-microvolt-speed3-pvs12-v1 = <780000 780000 1120000>;
			opp-microvolt-speed3-pvs13-v1 = <775000 775000 1120000>;
			opp-microvolt-speed3-pvs14-v1 = <765000 765000 1120000>;
			opp-microvolt-speed3-pvs15-v1 = <760000 760000 1120000>;
		};

		opp-1036800000 {
			opp-hz = /bits/ 64 <1036800000>;
			opp-supported-hw = <0xf>;
			opp-microvolt-speed0-pvs0-v0 = <925000 925000 1120000>;
			opp-microvolt-speed0-pvs1-v0 = <910000 910000 1120000>;
			opp-microvolt-speed0-pvs2-v0 = <890000 890000 1120000>;
			opp-microvolt-speed0-pvs3-v0 = <875000 875000 1120000>;
			opp-microvolt-speed0-pvs4-v0 = <860000 860000 1120000>;
			opp-microvolt-speed0-pvs5-v0 = <850000 850000 1120000>;
			opp-microvolt-speed0-pvs6-v0 = <840000 840000 1120000>;
			opp-microvolt-speed1-pvs0-v0 = <850000 850000 1120000>;
			opp-microvolt-speed1-pvs0-v1 = <900000 900000 1120000>;
			opp-microvolt-speed1-pvs1-v0 = <835000 835000 1120000>;
			opp-microvolt-speed1-pvs1-v1 = <890000 890000 1120000>;
			opp-microvolt-speed1-pvs2-v0 = <820000 820000 1120000>;
			opp-microvolt-speed1-pvs2-v1 = <880000 880000 1120000>;
			opp-microvolt-speed1-pvs3-v0 = <805000 805000 1120000>;
			opp-microvolt-speed1-pvs3-v1 = <870000 870000 1120000>;
			opp-microvolt-speed1-pvs4-v0 = <795000 795000 1120000>;
			opp-microvolt-speed1-pvs4-v1 = <860000 860000 1120000>;
			opp-microvolt-speed1-pvs5-v0 = <785000 785000 1120000>;
			opp-microvolt-speed1-pvs5-v1 = <850000 850000 1120000>;
			opp-microvolt-speed1-pvs6-v0 = <775000 775000 1120000>;
			opp-microvolt-speed1-pvs6-v1 = <845000 845000 1120000>;
			opp-microvolt-speed1-pvs7-v1 = <840000 840000 1120000>;
			opp-microvolt-speed1-pvs8-v1 = <830000 830000 1120000>;
			opp-microvolt-speed1-pvs9-v1 = <825000 825000 1120000>;
			opp-microvolt-speed1-pvs10-v1 = <820000 820000 1120000>;
			opp-microvolt-speed1-pvs11-v1 = <815000 815000 1120000>;
			opp-microvolt-speed1-pvs12-v1 = <810000 810000 1120000>;
			opp-microvolt-speed1-pvs13-v1 = <805000 805000 1120000>;
			opp-microvolt-speed1-pvs14-v1 = <800000 800000 1120000>;
			opp-microvolt-speed1-pvs15-v1 = <795000 795000 1120000>;
			opp-microvolt-speed2-pvs0-v0 = <890000 890000 1120000>;
			opp-microvolt-speed2-pvs1-v0 = <875000 875000 1120000>;
			opp-microvolt-speed2-pvs2-v0 = <855000 855000 1120000>;
			opp-microvolt-speed2-pvs3-v0 = <840000 840000 1120000>;
			opp-microvolt-speed2-pvs4-v0 = <830000 830000 1120000>;
			opp-microvolt-speed2-pvs5-v0 = <820000 820000 1120000>;
			opp-microvolt-speed2-pvs6-v0 = <810000 810000 1120000>;
			opp-microvolt-speed3-pvs0-v0 = <860000 860000 1120000>;
			opp-microvolt-speed3-pvs0-v1 = <880000 880000 1120000>;
			opp-microvolt-speed3-pvs1-v0 = <835000 835000 1120000>;
			opp-microvolt-speed3-pvs1-v1 = <870000 870000 1120000>;
			opp-microvolt-speed3-pvs2-v0 = <810000 810000 1120000>;
			opp-microvolt-speed3-pvs2-v1 = <860000 860000 1120000>;
			opp-microvolt-speed3-pvs3-v0 = <785000 785000 1120000>;
			opp-microvolt-speed3-pvs3-v1 = <850000 850000 1120000>;
			opp-microvolt-speed3-pvs4-v0 = <775000 775000 1120000>;
			opp-microvolt-speed3-pvs4-v1 = <840000 840000 1120000>;
			opp-microvolt-speed3-pvs5-v0 = <750000 750000 1120000>;
			opp-microvolt-speed3-pvs5-v1 = <830000 830000 1120000>;
			opp-microvolt-speed3-pvs6-v0 = <750000 750000 1120000>;
			opp-microvolt-speed3-pvs6-v1 = <820000 820000 1120000>;
			opp-microvolt-speed3-pvs7-v1 = <815000 815000 1120000>;
			opp-microvolt-speed3-pvs8-v1 = <805000 805000 1120000>;
			opp-microvolt-speed3-pvs9-v1 = <800000 800000 1120000>;
			opp-microvolt-speed3-pvs10-v1 = <795000 795000 1120000>;
			opp-microvolt-speed3-pvs11-v1 = <790000 790000 1120000>;
			opp-microvolt-speed3-pvs12-v1 = <785000 785000 1120000>;
			opp-microvolt-speed3-pvs13-v1 = <780000 780000 1120000>;
			opp-microvolt-speed3-pvs14-v1 = <775000 775000 1120000>;
			opp-microvolt-speed3-pvs15-v1 = <770000 770000 1120000>;
			status = "disabled";	/* above the safe rail cap */
		};

		opp-1113600000 {
			opp-hz = /bits/ 64 <1113600000>;
			opp-supported-hw = <0xf>;
			opp-microvolt-speed0-pvs0-v0 = <940000 940000 1120000>;
			opp-microvolt-speed0-pvs1-v0 = <920000 920000 1120000>;
			opp-microvolt-speed0-pvs2-v0 = <900000 900000 1120000>;
			opp-microvolt-speed0-pvs3-v0 = <885000 885000 1120000>;
			opp-microvolt-speed0-pvs4-v0 = <870000 870000 1120000>;
			opp-microvolt-speed0-pvs5-v0 = <860000 860000 1120000>;
			opp-microvolt-speed0-pvs6-v0 = <850000 850000 1120000>;
			opp-microvolt-speed1-pvs0-v0 = <865000 865000 1120000>;
			opp-microvolt-speed1-pvs0-v1 = <910000 910000 1120000>;
			opp-microvolt-speed1-pvs1-v0 = <850000 850000 1120000>;
			opp-microvolt-speed1-pvs1-v1 = <900000 900000 1120000>;
			opp-microvolt-speed1-pvs2-v0 = <830000 830000 1120000>;
			opp-microvolt-speed1-pvs2-v1 = <890000 890000 1120000>;
			opp-microvolt-speed1-pvs3-v0 = <815000 815000 1120000>;
			opp-microvolt-speed1-pvs3-v1 = <880000 880000 1120000>;
			opp-microvolt-speed1-pvs4-v0 = <805000 805000 1120000>;
			opp-microvolt-speed1-pvs4-v1 = <870000 870000 1120000>;
			opp-microvolt-speed1-pvs5-v0 = <795000 795000 1120000>;
			opp-microvolt-speed1-pvs5-v1 = <860000 860000 1120000>;
			opp-microvolt-speed1-pvs6-v0 = <785000 785000 1120000>;
			opp-microvolt-speed1-pvs6-v1 = <855000 855000 1120000>;
			opp-microvolt-speed1-pvs7-v1 = <850000 850000 1120000>;
			opp-microvolt-speed1-pvs8-v1 = <840000 840000 1120000>;
			opp-microvolt-speed1-pvs9-v1 = <835000 835000 1120000>;
			opp-microvolt-speed1-pvs10-v1 = <830000 830000 1120000>;
			opp-microvolt-speed1-pvs11-v1 = <825000 825000 1120000>;
			opp-microvolt-speed1-pvs12-v1 = <820000 820000 1120000>;
			opp-microvolt-speed1-pvs13-v1 = <815000 815000 1120000>;
			opp-microvolt-speed1-pvs14-v1 = <810000 810000 1120000>;
			opp-microvolt-speed1-pvs15-v1 = <805000 805000 1120000>;
			opp-microvolt-speed2-pvs0-v0 = <900000 900000 1120000>;
			opp-microvolt-speed2-pvs1-v0 = <885000 885000 1120000>;
			opp-microvolt-speed2-pvs2-v0 = <865000 865000 1120000>;
			opp-microvolt-speed2-pvs3-v0 = <850000 850000 1120000>;
			opp-microvolt-speed2-pvs4-v0 = <840000 840000 1120000>;
			opp-microvolt-speed2-pvs5-v0 = <830000 830000 1120000>;
			opp-microvolt-speed2-pvs6-v0 = <820000 820000 1120000>;
			opp-microvolt-speed3-pvs0-v0 = <870000 870000 1120000>;
			opp-microvolt-speed3-pvs0-v1 = <890000 890000 1120000>;
			opp-microvolt-speed3-pvs1-v0 = <845000 845000 1120000>;
			opp-microvolt-speed3-pvs1-v1 = <880000 880000 1120000>;
			opp-microvolt-speed3-pvs2-v0 = <820000 820000 1120000>;
			opp-microvolt-speed3-pvs2-v1 = <870000 870000 1120000>;
			opp-microvolt-speed3-pvs3-v0 = <795000 795000 1120000>;
			opp-microvolt-speed3-pvs3-v1 = <860000 860000 1120000>;
			opp-microvolt-speed3-pvs4-v0 = <775000 775000 1120000>;
			opp-microvolt-speed3-pvs4-v1 = <850000 850000 1120000>;
			opp-microvolt-speed3-pvs5-v0 = <750000 750000 1120000>;
			opp-microvolt-speed3-pvs5-v1 = <840000 840000 1120000>;
			opp-microvolt-speed3-pvs6-v0 = <750000 750000 1120000>;
			opp-microvolt-speed3-pvs6-v1 = <830000 830000 1120000>;
			opp-microvolt-speed3-pvs7-v1 = <825000 825000 1120000>;
			opp-microvolt-speed3-pvs8-v1 = <815000 815000 1120000>;
			opp-microvolt-speed3-pvs9-v1 = <810000 810000 1120000>;
			opp-microvolt-speed3-pvs10-v1 = <805000 805000 1120000>;
			opp-microvolt-speed3-pvs11-v1 = <800000 800000 1120000>;
			opp-microvolt-speed3-pvs12-v1 = <795000 795000 1120000>;
			opp-microvolt-speed3-pvs13-v1 = <790000 790000 1120000>;
			opp-microvolt-speed3-pvs14-v1 = <785000 785000 1120000>;
			opp-microvolt-speed3-pvs15-v1 = <780000 780000 1120000>;
			status = "disabled";	/* above the safe rail cap */
		};

		opp-1190400000 {
			opp-hz = /bits/ 64 <1190400000>;
			opp-supported-hw = <0xf>;
			opp-microvolt-speed0-pvs0-v0 = <950000 950000 1120000>;
			opp-microvolt-speed0-pvs1-v0 = <930000 930000 1120000>;
			opp-microvolt-speed0-pvs2-v0 = <910000 910000 1120000>;
			opp-microvolt-speed0-pvs3-v0 = <895000 895000 1120000>;
			opp-microvolt-speed0-pvs4-v0 = <880000 880000 1120000>;
			opp-microvolt-speed0-pvs5-v0 = <870000 870000 1120000>;
			opp-microvolt-speed0-pvs6-v0 = <860000 860000 1120000>;
			opp-microvolt-speed1-pvs0-v0 = <875000 875000 1120000>;
			opp-microvolt-speed1-pvs0-v1 = <920000 920000 1120000>;
			opp-microvolt-speed1-pvs1-v0 = <860000 860000 1120000>;
			opp-microvolt-speed1-pvs1-v1 = <910000 910000 1120000>;
			opp-microvolt-speed1-pvs2-v0 = <840000 840000 1120000>;
			opp-microvolt-speed1-pvs2-v1 = <900000 900000 1120000>;
			opp-microvolt-speed1-pvs3-v0 = <825000 825000 1120000>;
			opp-microvolt-speed1-pvs3-v1 = <890000 890000 1120000>;
			opp-microvolt-speed1-pvs4-v0 = <815000 815000 1120000>;
			opp-microvolt-speed1-pvs4-v1 = <880000 880000 1120000>;
			opp-microvolt-speed1-pvs5-v0 = <805000 805000 1120000>;
			opp-microvolt-speed1-pvs5-v1 = <870000 870000 1120000>;
			opp-microvolt-speed1-pvs6-v0 = <795000 795000 1120000>;
			opp-microvolt-speed1-pvs6-v1 = <865000 865000 1120000>;
			opp-microvolt-speed1-pvs7-v1 = <860000 860000 1120000>;
			opp-microvolt-speed1-pvs8-v1 = <850000 850000 1120000>;
			opp-microvolt-speed1-pvs9-v1 = <845000 845000 1120000>;
			opp-microvolt-speed1-pvs10-v1 = <840000 840000 1120000>;
			opp-microvolt-speed1-pvs11-v1 = <835000 835000 1120000>;
			opp-microvolt-speed1-pvs12-v1 = <830000 830000 1120000>;
			opp-microvolt-speed1-pvs13-v1 = <825000 825000 1120000>;
			opp-microvolt-speed1-pvs14-v1 = <820000 820000 1120000>;
			opp-microvolt-speed1-pvs15-v1 = <815000 815000 1120000>;
			opp-microvolt-speed2-pvs0-v0 = <915000 915000 1120000>;
			opp-microvolt-speed2-pvs1-v0 = <895000 895000 1120000>;
			opp-microvolt-speed2-pvs2-v0 = <875000 875000 1120000>;
			opp-microvolt-speed2-pvs3-v0 = <860000 860000 1120000>;
			opp-microvolt-speed2-pvs4-v0 = <850000 850000 1120000>;
			opp-microvolt-speed2-pvs5-v0 = <840000 840000 1120000>;
			opp-microvolt-speed2-pvs6-v0 = <830000 830000 1120000>;
			opp-microvolt-speed3-pvs0-v0 = <880000 880000 1120000>;
			opp-microvolt-speed3-pvs0-v1 = <900000 900000 1120000>;
			opp-microvolt-speed3-pvs1-v0 = <855000 855000 1120000>;
			opp-microvolt-speed3-pvs1-v1 = <890000 890000 1120000>;
			opp-microvolt-speed3-pvs2-v0 = <830000 830000 1120000>;
			opp-microvolt-speed3-pvs2-v1 = <880000 880000 1120000>;
			opp-microvolt-speed3-pvs3-v0 = <805000 805000 1120000>;
			opp-microvolt-speed3-pvs3-v1 = <870000 870000 1120000>;
			opp-microvolt-speed3-pvs4-v0 = <780000 780000 1120000>;
			opp-microvolt-speed3-pvs4-v1 = <860000 860000 1120000>;
			opp-microvolt-speed3-pvs5-v0 = <760000 760000 1120000>;
			opp-microvolt-speed3-pvs5-v1 = <850000 850000 1120000>;
			opp-microvolt-speed3-pvs6-v0 = <750000 750000 1120000>;
			opp-microvolt-speed3-pvs6-v1 = <840000 840000 1120000>;
			opp-microvolt-speed3-pvs7-v1 = <835000 835000 1120000>;
			opp-microvolt-speed3-pvs8-v1 = <825000 825000 1120000>;
			opp-microvolt-speed3-pvs9-v1 = <820000 820000 1120000>;
			opp-microvolt-speed3-pvs10-v1 = <815000 815000 1120000>;
			opp-microvolt-speed3-pvs11-v1 = <810000 810000 1120000>;
			opp-microvolt-speed3-pvs12-v1 = <805000 805000 1120000>;
			opp-microvolt-speed3-pvs13-v1 = <800000 800000 1120000>;
			opp-microvolt-speed3-pvs14-v1 = <795000 795000 1120000>;
			opp-microvolt-speed3-pvs15-v1 = <790000 790000 1120000>;
			status = "disabled";	/* above the safe rail cap */
		};

		opp-1267200000 {
			opp-hz = /bits/ 64 <1267200000>;
			opp-supported-hw = <0xf>;
			opp-microvolt-speed0-pvs0-v0 = <965000 965000 1120000>;
			opp-microvolt-speed0-pvs1-v0 = <945000 945000 1120000>;
			opp-microvolt-speed0-pvs2-v0 = <925000 925000 1120000>;
			opp-microvolt-speed0-pvs3-v0 = <910000 910000 1120000>;
			opp-microvolt-speed0-pvs4-v0 = <895000 895000 1120000>;
			opp-microvolt-speed0-pvs5-v0 = <880000 880000 1120000>;
			opp-microvolt-speed0-pvs6-v0 = <870000 870000 1120000>;
			opp-microvolt-speed1-pvs0-v0 = <890000 890000 1120000>;
			opp-microvolt-speed1-pvs0-v1 = <930000 930000 1120000>;
			opp-microvolt-speed1-pvs1-v0 = <870000 870000 1120000>;
			opp-microvolt-speed1-pvs1-v1 = <920000 920000 1120000>;
			opp-microvolt-speed1-pvs2-v0 = <850000 850000 1120000>;
			opp-microvolt-speed1-pvs2-v1 = <910000 910000 1120000>;
			opp-microvolt-speed1-pvs3-v0 = <835000 835000 1120000>;
			opp-microvolt-speed1-pvs3-v1 = <900000 900000 1120000>;
			opp-microvolt-speed1-pvs4-v0 = <825000 825000 1120000>;
			opp-microvolt-speed1-pvs4-v1 = <890000 890000 1120000>;
			opp-microvolt-speed1-pvs5-v0 = <815000 815000 1120000>;
			opp-microvolt-speed1-pvs5-v1 = <880000 880000 1120000>;
			opp-microvolt-speed1-pvs6-v0 = <805000 805000 1120000>;
			opp-microvolt-speed1-pvs6-v1 = <875000 875000 1120000>;
			opp-microvolt-speed1-pvs7-v1 = <870000 870000 1120000>;
			opp-microvolt-speed1-pvs8-v1 = <860000 860000 1120000>;
			opp-microvolt-speed1-pvs9-v1 = <855000 855000 1120000>;
			opp-microvolt-speed1-pvs10-v1 = <850000 850000 1120000>;
			opp-microvolt-speed1-pvs11-v1 = <845000 845000 1120000>;
			opp-microvolt-speed1-pvs12-v1 = <840000 840000 1120000>;
			opp-microvolt-speed1-pvs13-v1 = <835000 835000 1120000>;
			opp-microvolt-speed1-pvs14-v1 = <830000 830000 1120000>;
			opp-microvolt-speed1-pvs15-v1 = <825000 825000 1120000>;
			opp-microvolt-speed2-pvs0-v0 = <925000 925000 1120000>;
			opp-microvolt-speed2-pvs1-v0 = <910000 910000 1120000>;
			opp-microvolt-speed2-pvs2-v0 = <890000 890000 1120000>;
			opp-microvolt-speed2-pvs3-v0 = <875000 875000 1120000>;
			opp-microvolt-speed2-pvs4-v0 = <860000 860000 1120000>;
			opp-microvolt-speed2-pvs5-v0 = <850000 850000 1120000>;
			opp-microvolt-speed2-pvs6-v0 = <840000 840000 1120000>;
			opp-microvolt-speed3-pvs0-v0 = <890000 890000 1120000>;
			opp-microvolt-speed3-pvs0-v1 = <910000 910000 1120000>;
			opp-microvolt-speed3-pvs1-v0 = <865000 865000 1120000>;
			opp-microvolt-speed3-pvs1-v1 = <900000 900000 1120000>;
			opp-microvolt-speed3-pvs2-v0 = <840000 840000 1120000>;
			opp-microvolt-speed3-pvs2-v1 = <890000 890000 1120000>;
			opp-microvolt-speed3-pvs3-v0 = <815000 815000 1120000>;
			opp-microvolt-speed3-pvs3-v1 = <880000 880000 1120000>;
			opp-microvolt-speed3-pvs4-v0 = <790000 790000 1120000>;
			opp-microvolt-speed3-pvs4-v1 = <870000 870000 1120000>;
			opp-microvolt-speed3-pvs5-v0 = <770000 770000 1120000>;
			opp-microvolt-speed3-pvs5-v1 = <860000 860000 1120000>;
			opp-microvolt-speed3-pvs6-v0 = <755000 755000 1120000>;
			opp-microvolt-speed3-pvs6-v1 = <850000 850000 1120000>;
			opp-microvolt-speed3-pvs7-v1 = <845000 845000 1120000>;
			opp-microvolt-speed3-pvs8-v1 = <835000 835000 1120000>;
			opp-microvolt-speed3-pvs9-v1 = <830000 830000 1120000>;
			opp-microvolt-speed3-pvs10-v1 = <825000 825000 1120000>;
			opp-microvolt-speed3-pvs11-v1 = <820000 820000 1120000>;
			opp-microvolt-speed3-pvs12-v1 = <815000 815000 1120000>;
			opp-microvolt-speed3-pvs13-v1 = <810000 810000 1120000>;
			opp-microvolt-speed3-pvs14-v1 = <805000 805000 1120000>;
			opp-microvolt-speed3-pvs15-v1 = <800000 800000 1120000>;
			status = "disabled";	/* above the safe rail cap */
		};

		opp-1344000000 {
			opp-hz = /bits/ 64 <1344000000>;
			opp-supported-hw = <0xf>;
			opp-microvolt-speed0-pvs0-v0 = <980000 980000 1120000>;
			opp-microvolt-speed0-pvs1-v0 = <960000 960000 1120000>;
			opp-microvolt-speed0-pvs2-v0 = <940000 940000 1120000>;
			opp-microvolt-speed0-pvs3-v0 = <925000 925000 1120000>;
			opp-microvolt-speed0-pvs4-v0 = <910000 910000 1120000>;
			opp-microvolt-speed0-pvs5-v0 = <890000 890000 1120000>;
			opp-microvolt-speed0-pvs6-v0 = <875000 875000 1120000>;
			opp-microvolt-speed1-pvs0-v0 = <900000 900000 1120000>;
			opp-microvolt-speed1-pvs0-v1 = <940000 940000 1120000>;
			opp-microvolt-speed1-pvs1-v0 = <885000 885000 1120000>;
			opp-microvolt-speed1-pvs1-v1 = <930000 930000 1120000>;
			opp-microvolt-speed1-pvs2-v0 = <865000 865000 1120000>;
			opp-microvolt-speed1-pvs2-v1 = <920000 920000 1120000>;
			opp-microvolt-speed1-pvs3-v0 = <850000 850000 1120000>;
			opp-microvolt-speed1-pvs3-v1 = <910000 910000 1120000>;
			opp-microvolt-speed1-pvs4-v0 = <835000 835000 1120000>;
			opp-microvolt-speed1-pvs4-v1 = <900000 900000 1120000>;
			opp-microvolt-speed1-pvs5-v0 = <825000 825000 1120000>;
			opp-microvolt-speed1-pvs5-v1 = <890000 890000 1120000>;
			opp-microvolt-speed1-pvs6-v0 = <815000 815000 1120000>;
			opp-microvolt-speed1-pvs6-v1 = <885000 885000 1120000>;
			opp-microvolt-speed1-pvs7-v1 = <880000 880000 1120000>;
			opp-microvolt-speed1-pvs8-v1 = <870000 870000 1120000>;
			opp-microvolt-speed1-pvs9-v1 = <865000 865000 1120000>;
			opp-microvolt-speed1-pvs10-v1 = <860000 860000 1120000>;
			opp-microvolt-speed1-pvs11-v1 = <855000 855000 1120000>;
			opp-microvolt-speed1-pvs12-v1 = <850000 850000 1120000>;
			opp-microvolt-speed1-pvs13-v1 = <845000 845000 1120000>;
			opp-microvolt-speed1-pvs14-v1 = <840000 840000 1120000>;
			opp-microvolt-speed1-pvs15-v1 = <835000 835000 1120000>;
			opp-microvolt-speed2-pvs0-v0 = <940000 940000 1120000>;
			opp-microvolt-speed2-pvs1-v0 = <920000 920000 1120000>;
			opp-microvolt-speed2-pvs2-v0 = <900000 900000 1120000>;
			opp-microvolt-speed2-pvs3-v0 = <885000 885000 1120000>;
			opp-microvolt-speed2-pvs4-v0 = <870000 870000 1120000>;
			opp-microvolt-speed2-pvs5-v0 = <860000 860000 1120000>;
			opp-microvolt-speed2-pvs6-v0 = <850000 850000 1120000>;
			opp-microvolt-speed3-pvs0-v0 = <900000 900000 1120000>;
			opp-microvolt-speed3-pvs0-v1 = <920000 920000 1120000>;
			opp-microvolt-speed3-pvs1-v0 = <875000 875000 1120000>;
			opp-microvolt-speed3-pvs1-v1 = <910000 910000 1120000>;
			opp-microvolt-speed3-pvs2-v0 = <850000 850000 1120000>;
			opp-microvolt-speed3-pvs2-v1 = <900000 900000 1120000>;
			opp-microvolt-speed3-pvs3-v0 = <825000 825000 1120000>;
			opp-microvolt-speed3-pvs3-v1 = <890000 890000 1120000>;
			opp-microvolt-speed3-pvs4-v0 = <800000 800000 1120000>;
			opp-microvolt-speed3-pvs4-v1 = <880000 880000 1120000>;
			opp-microvolt-speed3-pvs5-v0 = <780000 780000 1120000>;
			opp-microvolt-speed3-pvs5-v1 = <870000 870000 1120000>;
			opp-microvolt-speed3-pvs6-v0 = <765000 765000 1120000>;
			opp-microvolt-speed3-pvs6-v1 = <860000 860000 1120000>;
			opp-microvolt-speed3-pvs7-v1 = <855000 855000 1120000>;
			opp-microvolt-speed3-pvs8-v1 = <845000 845000 1120000>;
			opp-microvolt-speed3-pvs9-v1 = <840000 840000 1120000>;
			opp-microvolt-speed3-pvs10-v1 = <835000 835000 1120000>;
			opp-microvolt-speed3-pvs11-v1 = <830000 830000 1120000>;
			opp-microvolt-speed3-pvs12-v1 = <825000 825000 1120000>;
			opp-microvolt-speed3-pvs13-v1 = <820000 820000 1120000>;
			opp-microvolt-speed3-pvs14-v1 = <815000 815000 1120000>;
			opp-microvolt-speed3-pvs15-v1 = <810000 810000 1120000>;
			status = "disabled";	/* above the safe rail cap */
		};

		opp-1420800000 {
			opp-hz = /bits/ 64 <1420800000>;
			opp-supported-hw = <0xf>;
			opp-microvolt-speed0-pvs0-v0 = <995000 995000 1120000>;
			opp-microvolt-speed0-pvs1-v0 = <975000 975000 1120000>;
			opp-microvolt-speed0-pvs2-v0 = <955000 955000 1120000>;
			opp-microvolt-speed0-pvs3-v0 = <935000 935000 1120000>;
			opp-microvolt-speed0-pvs4-v0 = <920000 920000 1120000>;
			opp-microvolt-speed0-pvs5-v0 = <900000 900000 1120000>;
			opp-microvolt-speed0-pvs6-v0 = <885000 885000 1120000>;
			opp-microvolt-speed1-pvs0-v0 = <915000 915000 1120000>;
			opp-microvolt-speed1-pvs0-v1 = <955000 955000 1120000>;
			opp-microvolt-speed1-pvs1-v0 = <895000 895000 1120000>;
			opp-microvolt-speed1-pvs1-v1 = <945000 945000 1120000>;
			opp-microvolt-speed1-pvs2-v0 = <875000 875000 1120000>;
			opp-microvolt-speed1-pvs2-v1 = <935000 935000 1120000>;
			opp-microvolt-speed1-pvs3-v0 = <860000 860000 1120000>;
			opp-microvolt-speed1-pvs3-v1 = <925000 925000 1120000>;
			opp-microvolt-speed1-pvs4-v0 = <845000 845000 1120000>;
			opp-microvolt-speed1-pvs4-v1 = <915000 915000 1120000>;
			opp-microvolt-speed1-pvs5-v0 = <835000 835000 1120000>;
			opp-microvolt-speed1-pvs5-v1 = <905000 905000 1120000>;
			opp-microvolt-speed1-pvs6-v0 = <825000 825000 1120000>;
			opp-microvolt-speed1-pvs6-v1 = <895000 895000 1120000>;
			opp-microvolt-speed1-pvs7-v1 = <890000 890000 1120000>;
			opp-microvolt-speed1-pvs8-v1 = <880000 880000 1120000>;
			opp-microvolt-speed1-pvs9-v1 = <875000 875000 1120000>;
			opp-microvolt-speed1-pvs10-v1 = <870000 870000 1120000>;
			opp-microvolt-speed1-pvs11-v1 = <865000 865000 1120000>;
			opp-microvolt-speed1-pvs12-v1 = <860000 860000 1120000>;
			opp-microvolt-speed1-pvs13-v1 = <855000 855000 1120000>;
			opp-microvolt-speed1-pvs14-v1 = <850000 850000 1120000>;
			opp-microvolt-speed1-pvs15-v1 = <845000 845000 1120000>;
			opp-microvolt-speed2-pvs0-v0 = <950000 950000 1120000>;
			opp-microvolt-speed2-pvs1-v0 = <930000 930000 1120000>;
			opp-microvolt-speed2-pvs2-v0 = <910000 910000 1120000>;
			opp-microvolt-speed2-pvs3-v0 = <895000 895000 1120000>;
			opp-microvolt-speed2-pvs4-v0 = <880000 880000 1120000>;
			opp-microvolt-speed2-pvs5-v0 = <870000 870000 1120000>;
			opp-microvolt-speed2-pvs6-v0 = <860000 860000 1120000>;
			opp-microvolt-speed3-pvs0-v0 = <910000 910000 1120000>;
			opp-microvolt-speed3-pvs0-v1 = <930000 930000 1120000>;
			opp-microvolt-speed3-pvs1-v0 = <885000 885000 1120000>;
			opp-microvolt-speed3-pvs1-v1 = <920000 920000 1120000>;
			opp-microvolt-speed3-pvs2-v0 = <860000 860000 1120000>;
			opp-microvolt-speed3-pvs2-v1 = <910000 910000 1120000>;
			opp-microvolt-speed3-pvs3-v0 = <835000 835000 1120000>;
			opp-microvolt-speed3-pvs3-v1 = <900000 900000 1120000>;
			opp-microvolt-speed3-pvs4-v0 = <810000 810000 1120000>;
			opp-microvolt-speed3-pvs4-v1 = <890000 890000 1120000>;
			opp-microvolt-speed3-pvs5-v0 = <790000 790000 1120000>;
			opp-microvolt-speed3-pvs5-v1 = <880000 880000 1120000>;
			opp-microvolt-speed3-pvs6-v0 = <775000 775000 1120000>;
			opp-microvolt-speed3-pvs6-v1 = <870000 870000 1120000>;
			opp-microvolt-speed3-pvs7-v1 = <865000 865000 1120000>;
			opp-microvolt-speed3-pvs8-v1 = <855000 855000 1120000>;
			opp-microvolt-speed3-pvs9-v1 = <850000 850000 1120000>;
			opp-microvolt-speed3-pvs10-v1 = <845000 845000 1120000>;
			opp-microvolt-speed3-pvs11-v1 = <840000 840000 1120000>;
			opp-microvolt-speed3-pvs12-v1 = <835000 835000 1120000>;
			opp-microvolt-speed3-pvs13-v1 = <830000 830000 1120000>;
			opp-microvolt-speed3-pvs14-v1 = <825000 825000 1120000>;
			opp-microvolt-speed3-pvs15-v1 = <820000 820000 1120000>;
			status = "disabled";	/* above the safe rail cap */
		};

		opp-1497600000 {
			opp-hz = /bits/ 64 <1497600000>;
			opp-supported-hw = <0xf>;
			opp-microvolt-speed0-pvs0-v0 = <1010000 1010000 1120000>;
			opp-microvolt-speed0-pvs1-v0 = <990000 990000 1120000>;
			opp-microvolt-speed0-pvs2-v0 = <970000 970000 1120000>;
			opp-microvolt-speed0-pvs3-v0 = <950000 950000 1120000>;
			opp-microvolt-speed0-pvs4-v0 = <930000 930000 1120000>;
			opp-microvolt-speed0-pvs5-v0 = <910000 910000 1120000>;
			opp-microvolt-speed0-pvs6-v0 = <895000 895000 1120000>;
			opp-microvolt-speed1-pvs0-v0 = <925000 925000 1120000>;
			opp-microvolt-speed1-pvs0-v1 = <970000 970000 1120000>;
			opp-microvolt-speed1-pvs1-v0 = <905000 905000 1120000>;
			opp-microvolt-speed1-pvs1-v1 = <960000 960000 1120000>;
			opp-microvolt-speed1-pvs2-v0 = <885000 885000 1120000>;
			opp-microvolt-speed1-pvs2-v1 = <950000 950000 1120000>;
			opp-microvolt-speed1-pvs3-v0 = <870000 870000 1120000>;
			opp-microvolt-speed1-pvs3-v1 = <940000 940000 1120000>;
			opp-microvolt-speed1-pvs4-v0 = <855000 855000 1120000>;
			opp-microvolt-speed1-pvs4-v1 = <930000 930000 1120000>;
			opp-microvolt-speed1-pvs5-v0 = <845000 845000 1120000>;
			opp-microvolt-speed1-pvs5-v1 = <920000 920000 1120000>;
			opp-microvolt-speed1-pvs6-v0 = <835000 835000 1120000>;
			opp-microvolt-speed1-pvs6-v1 = <910000 910000 1120000>;
			opp-microvolt-speed1-pvs7-v1 = <900000 900000 1120000>;
			opp-microvolt-speed1-pvs8-v1 = <890000 890000 1120000>;
			opp-microvolt-speed1-pvs9-v1 = <885000 885000 1120000>;
			opp-microvolt-speed1-pvs10-v1 = <880000 880000 1120000>;
			opp-microvolt-speed1-pvs11-v1 = <875000 875000 1120000>;
			opp-microvolt-speed1-pvs12-v1 = <870000 870000 1120000>;
			opp-microvolt-speed1-pvs13-v1 = <865000 865000 1120000>;
			opp-microvolt-speed1-pvs14-v1 = <860000 860000 1120000>;
			opp-microvolt-speed1-pvs15-v1 = <855000 855000 1120000>;
			opp-microvolt-speed2-pvs0-v0 = <965000 965000 1120000>;
			opp-microvolt-speed2-pvs1-v0 = <945000 945000 1120000>;
			opp-microvolt-speed2-pvs2-v0 = <925000 925000 1120000>;
			opp-microvolt-speed2-pvs3-v0 = <910000 910000 1120000>;
			opp-microvolt-speed2-pvs4-v0 = <895000 895000 1120000>;
			opp-microvolt-speed2-pvs5-v0 = <880000 880000 1120000>;
			opp-microvolt-speed2-pvs6-v0 = <870000 870000 1120000>;
			opp-microvolt-speed3-pvs0-v0 = <920000 920000 1120000>;
			opp-microvolt-speed3-pvs0-v1 = <940000 940000 1120000>;
			opp-microvolt-speed3-pvs1-v0 = <895000 895000 1120000>;
			opp-microvolt-speed3-pvs1-v1 = <930000 930000 1120000>;
			opp-microvolt-speed3-pvs2-v0 = <870000 870000 1120000>;
			opp-microvolt-speed3-pvs2-v1 = <920000 920000 1120000>;
			opp-microvolt-speed3-pvs3-v0 = <845000 845000 1120000>;
			opp-microvolt-speed3-pvs3-v1 = <910000 910000 1120000>;
			opp-microvolt-speed3-pvs4-v0 = <820000 820000 1120000>;
			opp-microvolt-speed3-pvs4-v1 = <900000 900000 1120000>;
			opp-microvolt-speed3-pvs5-v0 = <800000 800000 1120000>;
			opp-microvolt-speed3-pvs5-v1 = <890000 890000 1120000>;
			opp-microvolt-speed3-pvs6-v0 = <785000 785000 1120000>;
			opp-microvolt-speed3-pvs6-v1 = <880000 880000 1120000>;
			opp-microvolt-speed3-pvs7-v1 = <875000 875000 1120000>;
			opp-microvolt-speed3-pvs8-v1 = <865000 865000 1120000>;
			opp-microvolt-speed3-pvs9-v1 = <860000 860000 1120000>;
			opp-microvolt-speed3-pvs10-v1 = <855000 855000 1120000>;
			opp-microvolt-speed3-pvs11-v1 = <850000 850000 1120000>;
			opp-microvolt-speed3-pvs12-v1 = <845000 845000 1120000>;
			opp-microvolt-speed3-pvs13-v1 = <840000 840000 1120000>;
			opp-microvolt-speed3-pvs14-v1 = <835000 835000 1120000>;
			opp-microvolt-speed3-pvs15-v1 = <830000 830000 1120000>;
			status = "disabled";	/* above the safe rail cap */
		};

		opp-1574400000 {
			opp-hz = /bits/ 64 <1574400000>;
			opp-supported-hw = <0xf>;
			opp-microvolt-speed0-pvs0-v0 = <1025000 1025000 1120000>;
			opp-microvolt-speed0-pvs1-v0 = <1005000 1005000 1120000>;
			opp-microvolt-speed0-pvs2-v0 = <980000 980000 1120000>;
			opp-microvolt-speed0-pvs3-v0 = <960000 960000 1120000>;
			opp-microvolt-speed0-pvs4-v0 = <940000 940000 1120000>;
			opp-microvolt-speed0-pvs5-v0 = <920000 920000 1120000>;
			opp-microvolt-speed0-pvs6-v0 = <905000 905000 1120000>;
			opp-microvolt-speed1-pvs0-v0 = <940000 940000 1120000>;
			opp-microvolt-speed1-pvs0-v1 = <985000 985000 1120000>;
			opp-microvolt-speed1-pvs1-v0 = <920000 920000 1120000>;
			opp-microvolt-speed1-pvs1-v1 = <975000 975000 1120000>;
			opp-microvolt-speed1-pvs2-v0 = <900000 900000 1120000>;
			opp-microvolt-speed1-pvs2-v1 = <965000 965000 1120000>;
			opp-microvolt-speed1-pvs3-v0 = <885000 885000 1120000>;
			opp-microvolt-speed1-pvs3-v1 = <955000 955000 1120000>;
			opp-microvolt-speed1-pvs4-v0 = <870000 870000 1120000>;
			opp-microvolt-speed1-pvs4-v1 = <945000 945000 1120000>;
			opp-microvolt-speed1-pvs5-v0 = <855000 855000 1120000>;
			opp-microvolt-speed1-pvs5-v1 = <935000 935000 1120000>;
			opp-microvolt-speed1-pvs6-v0 = <845000 845000 1120000>;
			opp-microvolt-speed1-pvs6-v1 = <925000 925000 1120000>;
			opp-microvolt-speed1-pvs7-v1 = <915000 915000 1120000>;
			opp-microvolt-speed1-pvs8-v1 = <905000 905000 1120000>;
			opp-microvolt-speed1-pvs9-v1 = <895000 895000 1120000>;
			opp-microvolt-speed1-pvs10-v1 = <890000 890000 1120000>;
			opp-microvolt-speed1-pvs11-v1 = <885000 885000 1120000>;
			opp-microvolt-speed1-pvs12-v1 = <880000 880000 1120000>;
			opp-microvolt-speed1-pvs13-v1 = <875000 875000 1120000>;
			opp-microvolt-speed1-pvs14-v1 = <870000 870000 1120000>;
			opp-microvolt-speed1-pvs15-v1 = <865000 865000 1120000>;
			opp-microvolt-speed2-pvs0-v0 = <980000 980000 1120000>;
			opp-microvolt-speed2-pvs1-v0 = <960000 960000 1120000>;
			opp-microvolt-speed2-pvs2-v0 = <940000 940000 1120000>;
			opp-microvolt-speed2-pvs3-v0 = <925000 925000 1120000>;
			opp-microvolt-speed2-pvs4-v0 = <910000 910000 1120000>;
			opp-microvolt-speed2-pvs5-v0 = <890000 890000 1120000>;
			opp-microvolt-speed2-pvs6-v0 = <875000 875000 1120000>;
			opp-microvolt-speed3-pvs0-v0 = <930000 930000 1120000>;
			opp-microvolt-speed3-pvs0-v1 = <950000 950000 1120000>;
			opp-microvolt-speed3-pvs1-v0 = <905000 905000 1120000>;
			opp-microvolt-speed3-pvs1-v1 = <940000 940000 1120000>;
			opp-microvolt-speed3-pvs2-v0 = <880000 880000 1120000>;
			opp-microvolt-speed3-pvs2-v1 = <930000 930000 1120000>;
			opp-microvolt-speed3-pvs3-v0 = <855000 855000 1120000>;
			opp-microvolt-speed3-pvs3-v1 = <920000 920000 1120000>;
			opp-microvolt-speed3-pvs4-v0 = <830000 830000 1120000>;
			opp-microvolt-speed3-pvs4-v1 = <910000 910000 1120000>;
			opp-microvolt-speed3-pvs5-v0 = <810000 810000 1120000>;
			opp-microvolt-speed3-pvs5-v1 = <900000 900000 1120000>;
			opp-microvolt-speed3-pvs6-v0 = <795000 795000 1120000>;
			opp-microvolt-speed3-pvs6-v1 = <890000 890000 1120000>;
			opp-microvolt-speed3-pvs7-v1 = <885000 885000 1120000>;
			opp-microvolt-speed3-pvs8-v1 = <875000 875000 1120000>;
			opp-microvolt-speed3-pvs9-v1 = <870000 870000 1120000>;
			opp-microvolt-speed3-pvs10-v1 = <865000 865000 1120000>;
			opp-microvolt-speed3-pvs11-v1 = <860000 860000 1120000>;
			opp-microvolt-speed3-pvs12-v1 = <855000 855000 1120000>;
			opp-microvolt-speed3-pvs13-v1 = <850000 850000 1120000>;
			opp-microvolt-speed3-pvs14-v1 = <845000 845000 1120000>;
			opp-microvolt-speed3-pvs15-v1 = <840000 840000 1120000>;
			status = "disabled";	/* above the safe rail cap */
		};

		opp-1651200000 {
			opp-hz = /bits/ 64 <1651200000>;
			opp-supported-hw = <0xf>;
			opp-microvolt-speed0-pvs0-v0 = <1040000 1040000 1120000>;
			opp-microvolt-speed0-pvs1-v0 = <1020000 1020000 1120000>;
			opp-microvolt-speed0-pvs2-v0 = <995000 995000 1120000>;
			opp-microvolt-speed0-pvs3-v0 = <970000 970000 1120000>;
			opp-microvolt-speed0-pvs4-v0 = <950000 950000 1120000>;
			opp-microvolt-speed0-pvs5-v0 = <930000 930000 1120000>;
			opp-microvolt-speed0-pvs6-v0 = <915000 915000 1120000>;
			opp-microvolt-speed1-pvs0-v0 = <955000 955000 1120000>;
			opp-microvolt-speed1-pvs0-v1 = <1000000 1000000 1120000>;
			opp-microvolt-speed1-pvs1-v0 = <935000 935000 1120000>;
			opp-microvolt-speed1-pvs1-v1 = <990000 990000 1120000>;
			opp-microvolt-speed1-pvs2-v0 = <915000 915000 1120000>;
			opp-microvolt-speed1-pvs2-v1 = <980000 980000 1120000>;
			opp-microvolt-speed1-pvs3-v0 = <900000 900000 1120000>;
			opp-microvolt-speed1-pvs3-v1 = <970000 970000 1120000>;
			opp-microvolt-speed1-pvs4-v0 = <885000 885000 1120000>;
			opp-microvolt-speed1-pvs4-v1 = <960000 960000 1120000>;
			opp-microvolt-speed1-pvs5-v0 = <865000 865000 1120000>;
			opp-microvolt-speed1-pvs5-v1 = <950000 950000 1120000>;
			opp-microvolt-speed1-pvs6-v0 = <850000 850000 1120000>;
			opp-microvolt-speed1-pvs6-v1 = <940000 940000 1120000>;
			opp-microvolt-speed1-pvs7-v1 = <930000 930000 1120000>;
			opp-microvolt-speed1-pvs8-v1 = <920000 920000 1120000>;
			opp-microvolt-speed1-pvs9-v1 = <910000 910000 1120000>;
			opp-microvolt-speed1-pvs10-v1 = <900000 900000 1120000>;
			opp-microvolt-speed1-pvs11-v1 = <895000 895000 1120000>;
			opp-microvolt-speed1-pvs12-v1 = <890000 890000 1120000>;
			opp-microvolt-speed1-pvs13-v1 = <885000 885000 1120000>;
			opp-microvolt-speed1-pvs14-v1 = <880000 880000 1120000>;
			opp-microvolt-speed1-pvs15-v1 = <875000 875000 1120000>;
			opp-microvolt-speed2-pvs0-v0 = <995000 995000 1120000>;
			opp-microvolt-speed2-pvs1-v0 = <975000 975000 1120000>;
			opp-microvolt-speed2-pvs2-v0 = <955000 955000 1120000>;
			opp-microvolt-speed2-pvs3-v0 = <935000 935000 1120000>;
			opp-microvolt-speed2-pvs4-v0 = <920000 920000 1120000>;
			opp-microvolt-speed2-pvs5-v0 = <900000 900000 1120000>;
			opp-microvolt-speed2-pvs6-v0 = <885000 885000 1120000>;
			opp-microvolt-speed3-pvs0-v0 = <945000 945000 1120000>;
			opp-microvolt-speed3-pvs0-v1 = <965000 965000 1120000>;
			opp-microvolt-speed3-pvs1-v0 = <920000 920000 1120000>;
			opp-microvolt-speed3-pvs1-v1 = <955000 955000 1120000>;
			opp-microvolt-speed3-pvs2-v0 = <895000 895000 1120000>;
			opp-microvolt-speed3-pvs2-v1 = <945000 945000 1120000>;
			opp-microvolt-speed3-pvs3-v0 = <870000 870000 1120000>;
			opp-microvolt-speed3-pvs3-v1 = <935000 935000 1120000>;
			opp-microvolt-speed3-pvs4-v0 = <845000 845000 1120000>;
			opp-microvolt-speed3-pvs4-v1 = <925000 925000 1120000>;
			opp-microvolt-speed3-pvs5-v0 = <820000 820000 1120000>;
			opp-microvolt-speed3-pvs5-v1 = <915000 915000 1120000>;
			opp-microvolt-speed3-pvs6-v0 = <805000 805000 1120000>;
			opp-microvolt-speed3-pvs6-v1 = <905000 905000 1120000>;
			opp-microvolt-speed3-pvs7-v1 = <895000 895000 1120000>;
			opp-microvolt-speed3-pvs8-v1 = <885000 885000 1120000>;
			opp-microvolt-speed3-pvs9-v1 = <880000 880000 1120000>;
			opp-microvolt-speed3-pvs10-v1 = <875000 875000 1120000>;
			opp-microvolt-speed3-pvs11-v1 = <870000 870000 1120000>;
			opp-microvolt-speed3-pvs12-v1 = <865000 865000 1120000>;
			opp-microvolt-speed3-pvs13-v1 = <860000 860000 1120000>;
			opp-microvolt-speed3-pvs14-v1 = <855000 855000 1120000>;
			opp-microvolt-speed3-pvs15-v1 = <850000 850000 1120000>;
			status = "disabled";	/* above the safe rail cap */
		};

		opp-1728000000 {
			opp-hz = /bits/ 64 <1728000000>;
			opp-supported-hw = <0xf>;
			opp-microvolt-speed0-pvs0-v0 = <1055000 1055000 1120000>;
			opp-microvolt-speed0-pvs1-v0 = <1030000 1030000 1120000>;
			opp-microvolt-speed0-pvs2-v0 = <1005000 1005000 1120000>;
			opp-microvolt-speed0-pvs3-v0 = <985000 985000 1120000>;
			opp-microvolt-speed0-pvs4-v0 = <960000 960000 1120000>;
			opp-microvolt-speed0-pvs5-v0 = <940000 940000 1120000>;
			opp-microvolt-speed0-pvs6-v0 = <920000 920000 1120000>;
			opp-microvolt-speed1-pvs0-v0 = <970000 970000 1120000>;
			opp-microvolt-speed1-pvs0-v1 = <1015000 1015000 1120000>;
			opp-microvolt-speed1-pvs1-v0 = <950000 950000 1120000>;
			opp-microvolt-speed1-pvs1-v1 = <1005000 1005000 1120000>;
			opp-microvolt-speed1-pvs2-v0 = <930000 930000 1120000>;
			opp-microvolt-speed1-pvs2-v1 = <995000 995000 1120000>;
			opp-microvolt-speed1-pvs3-v0 = <910000 910000 1120000>;
			opp-microvolt-speed1-pvs3-v1 = <985000 985000 1120000>;
			opp-microvolt-speed1-pvs4-v0 = <895000 895000 1120000>;
			opp-microvolt-speed1-pvs4-v1 = <975000 975000 1120000>;
			opp-microvolt-speed1-pvs5-v0 = <875000 875000 1120000>;
			opp-microvolt-speed1-pvs5-v1 = <965000 965000 1120000>;
			opp-microvolt-speed1-pvs6-v0 = <860000 860000 1120000>;
			opp-microvolt-speed1-pvs6-v1 = <955000 955000 1120000>;
			opp-microvolt-speed1-pvs7-v1 = <945000 945000 1120000>;
			opp-microvolt-speed1-pvs8-v1 = <935000 935000 1120000>;
			opp-microvolt-speed1-pvs9-v1 = <925000 925000 1120000>;
			opp-microvolt-speed1-pvs10-v1 = <915000 915000 1120000>;
			opp-microvolt-speed1-pvs11-v1 = <905000 905000 1120000>;
			opp-microvolt-speed1-pvs12-v1 = <900000 900000 1120000>;
			opp-microvolt-speed1-pvs13-v1 = <895000 895000 1120000>;
			opp-microvolt-speed1-pvs14-v1 = <890000 890000 1120000>;
			opp-microvolt-speed1-pvs15-v1 = <885000 885000 1120000>;
			opp-microvolt-speed2-pvs0-v0 = <1010000 1010000 1120000>;
			opp-microvolt-speed2-pvs1-v0 = <990000 990000 1120000>;
			opp-microvolt-speed2-pvs2-v0 = <970000 970000 1120000>;
			opp-microvolt-speed2-pvs3-v0 = <950000 950000 1120000>;
			opp-microvolt-speed2-pvs4-v0 = <930000 930000 1120000>;
			opp-microvolt-speed2-pvs5-v0 = <910000 910000 1120000>;
			opp-microvolt-speed2-pvs6-v0 = <895000 895000 1120000>;
			opp-microvolt-speed3-pvs0-v0 = <960000 960000 1120000>;
			opp-microvolt-speed3-pvs0-v1 = <980000 980000 1120000>;
			opp-microvolt-speed3-pvs1-v0 = <935000 935000 1120000>;
			opp-microvolt-speed3-pvs1-v1 = <970000 970000 1120000>;
			opp-microvolt-speed3-pvs2-v0 = <910000 910000 1120000>;
			opp-microvolt-speed3-pvs2-v1 = <960000 960000 1120000>;
			opp-microvolt-speed3-pvs3-v0 = <885000 885000 1120000>;
			opp-microvolt-speed3-pvs3-v1 = <950000 950000 1120000>;
			opp-microvolt-speed3-pvs4-v0 = <860000 860000 1120000>;
			opp-microvolt-speed3-pvs4-v1 = <940000 940000 1120000>;
			opp-microvolt-speed3-pvs5-v0 = <835000 835000 1120000>;
			opp-microvolt-speed3-pvs5-v1 = <930000 930000 1120000>;
			opp-microvolt-speed3-pvs6-v0 = <815000 815000 1120000>;
			opp-microvolt-speed3-pvs6-v1 = <920000 920000 1120000>;
			opp-microvolt-speed3-pvs7-v1 = <910000 910000 1120000>;
			opp-microvolt-speed3-pvs8-v1 = <900000 900000 1120000>;
			opp-microvolt-speed3-pvs9-v1 = <890000 890000 1120000>;
			opp-microvolt-speed3-pvs10-v1 = <885000 885000 1120000>;
			opp-microvolt-speed3-pvs11-v1 = <880000 880000 1120000>;
			opp-microvolt-speed3-pvs12-v1 = <875000 875000 1120000>;
			opp-microvolt-speed3-pvs13-v1 = <870000 870000 1120000>;
			opp-microvolt-speed3-pvs14-v1 = <865000 865000 1120000>;
			opp-microvolt-speed3-pvs15-v1 = <860000 860000 1120000>;
			status = "disabled";	/* above the safe rail cap */
		};

		opp-1804800000 {
			opp-hz = /bits/ 64 <1804800000>;
			opp-supported-hw = <0xf>;
			opp-microvolt-speed0-pvs0-v0 = <1070000 1070000 1120000>;
			opp-microvolt-speed0-pvs1-v0 = <1045000 1045000 1120000>;
			opp-microvolt-speed0-pvs2-v0 = <1020000 1020000 1120000>;
			opp-microvolt-speed0-pvs3-v0 = <995000 995000 1120000>;
			opp-microvolt-speed0-pvs4-v0 = <975000 975000 1120000>;
			opp-microvolt-speed0-pvs5-v0 = <955000 955000 1120000>;
			opp-microvolt-speed0-pvs6-v0 = <930000 930000 1120000>;
			opp-microvolt-speed1-pvs0-v0 = <985000 985000 1120000>;
			opp-microvolt-speed1-pvs0-v1 = <1030000 1030000 1120000>;
			opp-microvolt-speed1-pvs1-v0 = <965000 965000 1120000>;
			opp-microvolt-speed1-pvs1-v1 = <1020000 1020000 1120000>;
			opp-microvolt-speed1-pvs2-v0 = <945000 945000 1120000>;
			opp-microvolt-speed1-pvs2-v1 = <1010000 1010000 1120000>;
			opp-microvolt-speed1-pvs3-v0 = <925000 925000 1120000>;
			opp-microvolt-speed1-pvs3-v1 = <1000000 1000000 1120000>;
			opp-microvolt-speed1-pvs4-v0 = <905000 905000 1120000>;
			opp-microvolt-speed1-pvs4-v1 = <990000 990000 1120000>;
			opp-microvolt-speed1-pvs5-v0 = <885000 885000 1120000>;
			opp-microvolt-speed1-pvs5-v1 = <980000 980000 1120000>;
			opp-microvolt-speed1-pvs6-v0 = <870000 870000 1120000>;
			opp-microvolt-speed1-pvs6-v1 = <970000 970000 1120000>;
			opp-microvolt-speed1-pvs7-v1 = <960000 960000 1120000>;
			opp-microvolt-speed1-pvs8-v1 = <950000 950000 1120000>;
			opp-microvolt-speed1-pvs9-v1 = <940000 940000 1120000>;
			opp-microvolt-speed1-pvs10-v1 = <930000 930000 1120000>;
			opp-microvolt-speed1-pvs11-v1 = <920000 920000 1120000>;
			opp-microvolt-speed1-pvs12-v1 = <910000 910000 1120000>;
			opp-microvolt-speed1-pvs13-v1 = <905000 905000 1120000>;
			opp-microvolt-speed1-pvs14-v1 = <900000 900000 1120000>;
			opp-microvolt-speed1-pvs15-v1 = <895000 895000 1120000>;
			opp-microvolt-speed2-pvs0-v0 = <1025000 1025000 1120000>;
			opp-microvolt-speed2-pvs1-v0 = <1005000 1005000 1120000>;
			opp-microvolt-speed2-pvs2-v0 = <980000 980000 1120000>;
			opp-microvolt-speed2-pvs3-v0 = <960000 960000 1120000>;
			opp-microvolt-speed2-pvs4-v0 = <940000 940000 1120000>;
			opp-microvolt-speed2-pvs5-v0 = <920000 920000 1120000>;
			opp-microvolt-speed2-pvs6-v0 = <905000 905000 1120000>;
			opp-microvolt-speed3-pvs0-v0 = <975000 975000 1120000>;
			opp-microvolt-speed3-pvs0-v1 = <995000 995000 1120000>;
			opp-microvolt-speed3-pvs1-v0 = <950000 950000 1120000>;
			opp-microvolt-speed3-pvs1-v1 = <985000 985000 1120000>;
			opp-microvolt-speed3-pvs2-v0 = <925000 925000 1120000>;
			opp-microvolt-speed3-pvs2-v1 = <975000 975000 1120000>;
			opp-microvolt-speed3-pvs3-v0 = <900000 900000 1120000>;
			opp-microvolt-speed3-pvs3-v1 = <965000 965000 1120000>;
			opp-microvolt-speed3-pvs4-v0 = <875000 875000 1120000>;
			opp-microvolt-speed3-pvs4-v1 = <955000 955000 1120000>;
			opp-microvolt-speed3-pvs5-v0 = <850000 850000 1120000>;
			opp-microvolt-speed3-pvs5-v1 = <945000 945000 1120000>;
			opp-microvolt-speed3-pvs6-v0 = <825000 825000 1120000>;
			opp-microvolt-speed3-pvs6-v1 = <935000 935000 1120000>;
			opp-microvolt-speed3-pvs7-v1 = <925000 925000 1120000>;
			opp-microvolt-speed3-pvs8-v1 = <915000 915000 1120000>;
			opp-microvolt-speed3-pvs9-v1 = <905000 905000 1120000>;
			opp-microvolt-speed3-pvs10-v1 = <895000 895000 1120000>;
			opp-microvolt-speed3-pvs11-v1 = <890000 890000 1120000>;
			opp-microvolt-speed3-pvs12-v1 = <885000 885000 1120000>;
			opp-microvolt-speed3-pvs13-v1 = <880000 880000 1120000>;
			opp-microvolt-speed3-pvs14-v1 = <875000 875000 1120000>;
			opp-microvolt-speed3-pvs15-v1 = <870000 870000 1120000>;
			status = "disabled";	/* above the safe rail cap */
		};

		opp-1881600000 {
			opp-hz = /bits/ 64 <1881600000>;
			opp-supported-hw = <0xf>;
			opp-microvolt-speed0-pvs0-v0 = <1085000 1085000 1120000>;
			opp-microvolt-speed0-pvs1-v0 = <1060000 1060000 1120000>;
			opp-microvolt-speed0-pvs2-v0 = <1035000 1035000 1120000>;
			opp-microvolt-speed0-pvs3-v0 = <1010000 1010000 1120000>;
			opp-microvolt-speed0-pvs4-v0 = <985000 985000 1120000>;
			opp-microvolt-speed0-pvs5-v0 = <965000 965000 1120000>;
			opp-microvolt-speed0-pvs6-v0 = <940000 940000 1120000>;
			opp-microvolt-speed1-pvs0-v0 = <1000000 1000000 1120000>;
			opp-microvolt-speed1-pvs0-v1 = <1045000 1045000 1120000>;
			opp-microvolt-speed1-pvs1-v0 = <980000 980000 1120000>;
			opp-microvolt-speed1-pvs1-v1 = <1035000 1035000 1120000>;
			opp-microvolt-speed1-pvs2-v0 = <955000 955000 1120000>;
			opp-microvolt-speed1-pvs2-v1 = <1025000 1025000 1120000>;
			opp-microvolt-speed1-pvs3-v0 = <935000 935000 1120000>;
			opp-microvolt-speed1-pvs3-v1 = <1015000 1015000 1120000>;
			opp-microvolt-speed1-pvs4-v0 = <915000 915000 1120000>;
			opp-microvolt-speed1-pvs4-v1 = <1005000 1005000 1120000>;
			opp-microvolt-speed1-pvs5-v0 = <895000 895000 1120000>;
			opp-microvolt-speed1-pvs5-v1 = <995000 995000 1120000>;
			opp-microvolt-speed1-pvs6-v0 = <880000 880000 1120000>;
			opp-microvolt-speed1-pvs6-v1 = <985000 985000 1120000>;
			opp-microvolt-speed1-pvs7-v1 = <975000 975000 1120000>;
			opp-microvolt-speed1-pvs8-v1 = <965000 965000 1120000>;
			opp-microvolt-speed1-pvs9-v1 = <955000 955000 1120000>;
			opp-microvolt-speed1-pvs10-v1 = <945000 945000 1120000>;
			opp-microvolt-speed1-pvs11-v1 = <935000 935000 1120000>;
			opp-microvolt-speed1-pvs12-v1 = <925000 925000 1120000>;
			opp-microvolt-speed1-pvs13-v1 = <915000 915000 1120000>;
			opp-microvolt-speed1-pvs14-v1 = <910000 910000 1120000>;
			opp-microvolt-speed1-pvs15-v1 = <905000 905000 1120000>;
			opp-microvolt-speed2-pvs0-v0 = <1040000 1040000 1120000>;
			opp-microvolt-speed2-pvs1-v0 = <1020000 1020000 1120000>;
			opp-microvolt-speed2-pvs2-v0 = <995000 995000 1120000>;
			opp-microvolt-speed2-pvs3-v0 = <970000 970000 1120000>;
			opp-microvolt-speed2-pvs4-v0 = <950000 950000 1120000>;
			opp-microvolt-speed2-pvs5-v0 = <930000 930000 1120000>;
			opp-microvolt-speed2-pvs6-v0 = <915000 915000 1120000>;
			opp-microvolt-speed3-pvs0-v0 = <990000 990000 1120000>;
			opp-microvolt-speed3-pvs0-v1 = <1010000 1010000 1120000>;
			opp-microvolt-speed3-pvs1-v0 = <965000 965000 1120000>;
			opp-microvolt-speed3-pvs1-v1 = <1000000 1000000 1120000>;
			opp-microvolt-speed3-pvs2-v0 = <940000 940000 1120000>;
			opp-microvolt-speed3-pvs2-v1 = <990000 990000 1120000>;
			opp-microvolt-speed3-pvs3-v0 = <915000 915000 1120000>;
			opp-microvolt-speed3-pvs3-v1 = <980000 980000 1120000>;
			opp-microvolt-speed3-pvs4-v0 = <890000 890000 1120000>;
			opp-microvolt-speed3-pvs4-v1 = <970000 970000 1120000>;
			opp-microvolt-speed3-pvs5-v0 = <865000 865000 1120000>;
			opp-microvolt-speed3-pvs5-v1 = <960000 960000 1120000>;
			opp-microvolt-speed3-pvs6-v0 = <840000 840000 1120000>;
			opp-microvolt-speed3-pvs6-v1 = <950000 950000 1120000>;
			opp-microvolt-speed3-pvs7-v1 = <940000 940000 1120000>;
			opp-microvolt-speed3-pvs8-v1 = <930000 930000 1120000>;
			opp-microvolt-speed3-pvs9-v1 = <920000 920000 1120000>;
			opp-microvolt-speed3-pvs10-v1 = <910000 910000 1120000>;
			opp-microvolt-speed3-pvs11-v1 = <900000 900000 1120000>;
			opp-microvolt-speed3-pvs12-v1 = <895000 895000 1120000>;
			opp-microvolt-speed3-pvs13-v1 = <890000 890000 1120000>;
			opp-microvolt-speed3-pvs14-v1 = <885000 885000 1120000>;
			opp-microvolt-speed3-pvs15-v1 = <880000 880000 1120000>;
			status = "disabled";	/* above the safe rail cap */
		};

		opp-1958400000 {
			opp-hz = /bits/ 64 <1958400000>;
			opp-supported-hw = <0xf>;
			opp-microvolt-speed0-pvs0-v0 = <1100000 1100000 1120000>;
			opp-microvolt-speed0-pvs1-v0 = <1075000 1075000 1120000>;
			opp-microvolt-speed0-pvs2-v0 = <1050000 1050000 1120000>;
			opp-microvolt-speed0-pvs3-v0 = <1025000 1025000 1120000>;
			opp-microvolt-speed0-pvs4-v0 = <1000000 1000000 1120000>;
			opp-microvolt-speed0-pvs5-v0 = <975000 975000 1120000>;
			opp-microvolt-speed0-pvs6-v0 = <950000 950000 1120000>;
			opp-microvolt-speed1-pvs0-v0 = <1015000 1015000 1120000>;
			opp-microvolt-speed1-pvs0-v1 = <1060000 1060000 1120000>;
			opp-microvolt-speed1-pvs1-v0 = <995000 995000 1120000>;
			opp-microvolt-speed1-pvs1-v1 = <1050000 1050000 1120000>;
			opp-microvolt-speed1-pvs2-v0 = <970000 970000 1120000>;
			opp-microvolt-speed1-pvs2-v1 = <1040000 1040000 1120000>;
			opp-microvolt-speed1-pvs3-v0 = <945000 945000 1120000>;
			opp-microvolt-speed1-pvs3-v1 = <1030000 1030000 1120000>;
			opp-microvolt-speed1-pvs4-v0 = <925000 925000 1120000>;
			opp-microvolt-speed1-pvs4-v1 = <1020000 1020000 1120000>;
			opp-microvolt-speed1-pvs5-v0 = <905000 905000 1120000>;
			opp-microvolt-speed1-pvs5-v1 = <1010000 1010000 1120000>;
			opp-microvolt-speed1-pvs6-v0 = <890000 890000 1120000>;
			opp-microvolt-speed1-pvs6-v1 = <1000000 1000000 1120000>;
			opp-microvolt-speed1-pvs7-v1 = <990000 990000 1120000>;
			opp-microvolt-speed1-pvs8-v1 = <980000 980000 1120000>;
			opp-microvolt-speed1-pvs9-v1 = <970000 970000 1120000>;
			opp-microvolt-speed1-pvs10-v1 = <960000 960000 1120000>;
			opp-microvolt-speed1-pvs11-v1 = <950000 950000 1120000>;
			opp-microvolt-speed1-pvs12-v1 = <940000 940000 1120000>;
			opp-microvolt-speed1-pvs13-v1 = <930000 930000 1120000>;
			opp-microvolt-speed1-pvs14-v1 = <920000 920000 1120000>;
			opp-microvolt-speed1-pvs15-v1 = <915000 915000 1120000>;
			opp-microvolt-speed2-pvs0-v0 = <1055000 1055000 1120000>;
			opp-microvolt-speed2-pvs1-v0 = <1030000 1030000 1120000>;
			opp-microvolt-speed2-pvs2-v0 = <1005000 1005000 1120000>;
			opp-microvolt-speed2-pvs3-v0 = <985000 985000 1120000>;
			opp-microvolt-speed2-pvs4-v0 = <960000 960000 1120000>;
			opp-microvolt-speed2-pvs5-v0 = <940000 940000 1120000>;
			opp-microvolt-speed2-pvs6-v0 = <920000 920000 1120000>;
			opp-microvolt-speed3-pvs0-v0 = <1005000 1005000 1120000>;
			opp-microvolt-speed3-pvs0-v1 = <1025000 1025000 1120000>;
			opp-microvolt-speed3-pvs1-v0 = <980000 980000 1120000>;
			opp-microvolt-speed3-pvs1-v1 = <1015000 1015000 1120000>;
			opp-microvolt-speed3-pvs2-v0 = <955000 955000 1120000>;
			opp-microvolt-speed3-pvs2-v1 = <1005000 1005000 1120000>;
			opp-microvolt-speed3-pvs3-v0 = <930000 930000 1120000>;
			opp-microvolt-speed3-pvs3-v1 = <995000 995000 1120000>;
			opp-microvolt-speed3-pvs4-v0 = <905000 905000 1120000>;
			opp-microvolt-speed3-pvs4-v1 = <985000 985000 1120000>;
			opp-microvolt-speed3-pvs5-v0 = <880000 880000 1120000>;
			opp-microvolt-speed3-pvs5-v1 = <975000 975000 1120000>;
			opp-microvolt-speed3-pvs6-v0 = <855000 855000 1120000>;
			opp-microvolt-speed3-pvs6-v1 = <965000 965000 1120000>;
			opp-microvolt-speed3-pvs7-v1 = <955000 955000 1120000>;
			opp-microvolt-speed3-pvs8-v1 = <945000 945000 1120000>;
			opp-microvolt-speed3-pvs9-v1 = <935000 935000 1120000>;
			opp-microvolt-speed3-pvs10-v1 = <925000 925000 1120000>;
			opp-microvolt-speed3-pvs11-v1 = <915000 915000 1120000>;
			opp-microvolt-speed3-pvs12-v1 = <905000 905000 1120000>;
			opp-microvolt-speed3-pvs13-v1 = <900000 900000 1120000>;
			opp-microvolt-speed3-pvs14-v1 = <895000 895000 1120000>;
			opp-microvolt-speed3-pvs15-v1 = <890000 890000 1120000>;
			status = "disabled";	/* above the safe rail cap */
		};

		opp-2035200000 {
			opp-hz = /bits/ 64 <2035200000>;
			opp-supported-hw = <0xe>;
			opp-microvolt-speed1-pvs0-v0 = <1030000 1030000 1120000>;
			opp-microvolt-speed1-pvs0-v1 = <1075000 1075000 1120000>;
			opp-microvolt-speed1-pvs1-v0 = <1005000 1005000 1120000>;
			opp-microvolt-speed1-pvs1-v1 = <1065000 1065000 1120000>;
			opp-microvolt-speed1-pvs2-v0 = <980000 980000 1120000>;
			opp-microvolt-speed1-pvs2-v1 = <1055000 1055000 1120000>;
			opp-microvolt-speed1-pvs3-v0 = <960000 960000 1120000>;
			opp-microvolt-speed1-pvs3-v1 = <1045000 1045000 1120000>;
			opp-microvolt-speed1-pvs4-v0 = <935000 935000 1120000>;
			opp-microvolt-speed1-pvs4-v1 = <1035000 1035000 1120000>;
			opp-microvolt-speed1-pvs5-v0 = <915000 915000 1120000>;
			opp-microvolt-speed1-pvs5-v1 = <1025000 1025000 1120000>;
			opp-microvolt-speed1-pvs6-v0 = <895000 895000 1120000>;
			opp-microvolt-speed1-pvs6-v1 = <1015000 1015000 1120000>;
			opp-microvolt-speed1-pvs7-v1 = <1005000 1005000 1120000>;
			opp-microvolt-speed1-pvs8-v1 = <995000 995000 1120000>;
			opp-microvolt-speed1-pvs9-v1 = <985000 985000 1120000>;
			opp-microvolt-speed1-pvs10-v1 = <975000 975000 1120000>;
			opp-microvolt-speed1-pvs11-v1 = <965000 965000 1120000>;
			opp-microvolt-speed1-pvs12-v1 = <955000 955000 1120000>;
			opp-microvolt-speed1-pvs13-v1 = <945000 945000 1120000>;
			opp-microvolt-speed1-pvs14-v1 = <935000 935000 1120000>;
			opp-microvolt-speed1-pvs15-v1 = <925000 925000 1120000>;
			opp-microvolt-speed2-pvs0-v0 = <1070000 1070000 1120000>;
			opp-microvolt-speed2-pvs1-v0 = <1045000 1045000 1120000>;
			opp-microvolt-speed2-pvs2-v0 = <1020000 1020000 1120000>;
			opp-microvolt-speed2-pvs3-v0 = <995000 995000 1120000>;
			opp-microvolt-speed2-pvs4-v0 = <975000 975000 1120000>;
			opp-microvolt-speed2-pvs5-v0 = <955000 955000 1120000>;
			opp-microvolt-speed2-pvs6-v0 = <930000 930000 1120000>;
			opp-microvolt-speed3-pvs0-v0 = <1020000 1020000 1120000>;
			opp-microvolt-speed3-pvs0-v1 = <1040000 1040000 1120000>;
			opp-microvolt-speed3-pvs1-v0 = <995000 995000 1120000>;
			opp-microvolt-speed3-pvs1-v1 = <1030000 1030000 1120000>;
			opp-microvolt-speed3-pvs2-v0 = <970000 970000 1120000>;
			opp-microvolt-speed3-pvs2-v1 = <1020000 1020000 1120000>;
			opp-microvolt-speed3-pvs3-v0 = <945000 945000 1120000>;
			opp-microvolt-speed3-pvs3-v1 = <1010000 1010000 1120000>;
			opp-microvolt-speed3-pvs4-v0 = <920000 920000 1120000>;
			opp-microvolt-speed3-pvs4-v1 = <1000000 1000000 1120000>;
			opp-microvolt-speed3-pvs5-v0 = <895000 895000 1120000>;
			opp-microvolt-speed3-pvs5-v1 = <990000 990000 1120000>;
			opp-microvolt-speed3-pvs6-v0 = <870000 870000 1120000>;
			opp-microvolt-speed3-pvs6-v1 = <980000 980000 1120000>;
			opp-microvolt-speed3-pvs7-v1 = <970000 970000 1120000>;
			opp-microvolt-speed3-pvs8-v1 = <960000 960000 1120000>;
			opp-microvolt-speed3-pvs9-v1 = <950000 950000 1120000>;
			opp-microvolt-speed3-pvs10-v1 = <940000 940000 1120000>;
			opp-microvolt-speed3-pvs11-v1 = <930000 930000 1120000>;
			opp-microvolt-speed3-pvs12-v1 = <920000 920000 1120000>;
			opp-microvolt-speed3-pvs13-v1 = <910000 910000 1120000>;
			opp-microvolt-speed3-pvs14-v1 = <905000 905000 1120000>;
			opp-microvolt-speed3-pvs15-v1 = <900000 900000 1120000>;
			status = "disabled";	/* above the safe rail cap */
		};

		opp-2112000000 {
			opp-hz = /bits/ 64 <2112000000>;
			opp-supported-hw = <0xe>;
			opp-microvolt-speed1-pvs0-v0 = <1045000 1045000 1120000>;
			opp-microvolt-speed1-pvs0-v1 = <1090000 1090000 1120000>;
			opp-microvolt-speed1-pvs1-v0 = <1020000 1020000 1120000>;
			opp-microvolt-speed1-pvs1-v1 = <1080000 1080000 1120000>;
			opp-microvolt-speed1-pvs2-v0 = <995000 995000 1120000>;
			opp-microvolt-speed1-pvs2-v1 = <1070000 1070000 1120000>;
			opp-microvolt-speed1-pvs3-v0 = <970000 970000 1120000>;
			opp-microvolt-speed1-pvs3-v1 = <1060000 1060000 1120000>;
			opp-microvolt-speed1-pvs4-v0 = <950000 950000 1120000>;
			opp-microvolt-speed1-pvs4-v1 = <1050000 1050000 1120000>;
			opp-microvolt-speed1-pvs5-v0 = <930000 930000 1120000>;
			opp-microvolt-speed1-pvs5-v1 = <1040000 1040000 1120000>;
			opp-microvolt-speed1-pvs6-v0 = <905000 905000 1120000>;
			opp-microvolt-speed1-pvs6-v1 = <1030000 1030000 1120000>;
			opp-microvolt-speed1-pvs7-v1 = <1020000 1020000 1120000>;
			opp-microvolt-speed1-pvs8-v1 = <1010000 1010000 1120000>;
			opp-microvolt-speed1-pvs9-v1 = <1000000 1000000 1120000>;
			opp-microvolt-speed1-pvs10-v1 = <990000 990000 1120000>;
			opp-microvolt-speed1-pvs11-v1 = <980000 980000 1120000>;
			opp-microvolt-speed1-pvs12-v1 = <970000 970000 1120000>;
			opp-microvolt-speed1-pvs13-v1 = <960000 960000 1120000>;
			opp-microvolt-speed1-pvs14-v1 = <950000 950000 1120000>;
			opp-microvolt-speed1-pvs15-v1 = <940000 940000 1120000>;
			opp-microvolt-speed2-pvs0-v0 = <1085000 1085000 1120000>;
			opp-microvolt-speed2-pvs1-v0 = <1060000 1060000 1120000>;
			opp-microvolt-speed2-pvs2-v0 = <1035000 1035000 1120000>;
			opp-microvolt-speed2-pvs3-v0 = <1010000 1010000 1120000>;
			opp-microvolt-speed2-pvs4-v0 = <985000 985000 1120000>;
			opp-microvolt-speed2-pvs5-v0 = <965000 965000 1120000>;
			opp-microvolt-speed2-pvs6-v0 = <940000 940000 1120000>;
			opp-microvolt-speed3-pvs0-v0 = <1035000 1035000 1120000>;
			opp-microvolt-speed3-pvs0-v1 = <1055000 1055000 1120000>;
			opp-microvolt-speed3-pvs1-v0 = <1010000 1010000 1120000>;
			opp-microvolt-speed3-pvs1-v1 = <1045000 1045000 1120000>;
			opp-microvolt-speed3-pvs2-v0 = <985000 985000 1120000>;
			opp-microvolt-speed3-pvs2-v1 = <1035000 1035000 1120000>;
			opp-microvolt-speed3-pvs3-v0 = <960000 960000 1120000>;
			opp-microvolt-speed3-pvs3-v1 = <1025000 1025000 1120000>;
			opp-microvolt-speed3-pvs4-v0 = <935000 935000 1120000>;
			opp-microvolt-speed3-pvs4-v1 = <1015000 1015000 1120000>;
			opp-microvolt-speed3-pvs5-v0 = <910000 910000 1120000>;
			opp-microvolt-speed3-pvs5-v1 = <1005000 1005000 1120000>;
			opp-microvolt-speed3-pvs6-v0 = <885000 885000 1120000>;
			opp-microvolt-speed3-pvs6-v1 = <995000 995000 1120000>;
			opp-microvolt-speed3-pvs7-v1 = <985000 985000 1120000>;
			opp-microvolt-speed3-pvs8-v1 = <975000 975000 1120000>;
			opp-microvolt-speed3-pvs9-v1 = <965000 965000 1120000>;
			opp-microvolt-speed3-pvs10-v1 = <955000 955000 1120000>;
			opp-microvolt-speed3-pvs11-v1 = <945000 945000 1120000>;
			opp-microvolt-speed3-pvs12-v1 = <935000 935000 1120000>;
			opp-microvolt-speed3-pvs13-v1 = <925000 925000 1120000>;
			opp-microvolt-speed3-pvs14-v1 = <915000 915000 1120000>;
			opp-microvolt-speed3-pvs15-v1 = <910000 910000 1120000>;
			status = "disabled";	/* above the safe rail cap */
		};

		opp-2150400000 {
			opp-hz = /bits/ 64 <2150400000>;
			opp-supported-hw = <0xe>;
			opp-microvolt-speed1-pvs0-v0 = <1060000 1060000 1120000>;
			opp-microvolt-speed1-pvs0-v1 = <1105000 1105000 1120000>;
			opp-microvolt-speed1-pvs1-v0 = <1035000 1035000 1120000>;
			opp-microvolt-speed1-pvs1-v1 = <1095000 1095000 1120000>;
			opp-microvolt-speed1-pvs2-v0 = <1010000 1010000 1120000>;
			opp-microvolt-speed1-pvs2-v1 = <1085000 1085000 1120000>;
			opp-microvolt-speed1-pvs3-v0 = <985000 985000 1120000>;
			opp-microvolt-speed1-pvs3-v1 = <1075000 1075000 1120000>;
			opp-microvolt-speed1-pvs4-v0 = <960000 960000 1120000>;
			opp-microvolt-speed1-pvs4-v1 = <1065000 1065000 1120000>;
			opp-microvolt-speed1-pvs5-v0 = <940000 940000 1120000>;
			opp-microvolt-speed1-pvs5-v1 = <1055000 1055000 1120000>;
			opp-microvolt-speed1-pvs6-v0 = <915000 915000 1120000>;
			opp-microvolt-speed1-pvs6-v1 = <1045000 1045000 1120000>;
			opp-microvolt-speed1-pvs7-v1 = <1035000 1035000 1120000>;
			opp-microvolt-speed1-pvs8-v1 = <1025000 1025000 1120000>;
			opp-microvolt-speed1-pvs9-v1 = <1015000 1015000 1120000>;
			opp-microvolt-speed1-pvs10-v1 = <1005000 1005000 1120000>;
			opp-microvolt-speed1-pvs11-v1 = <995000 995000 1120000>;
			opp-microvolt-speed1-pvs12-v1 = <985000 985000 1120000>;
			opp-microvolt-speed1-pvs13-v1 = <975000 975000 1120000>;
			opp-microvolt-speed1-pvs14-v1 = <965000 965000 1120000>;
			opp-microvolt-speed1-pvs15-v1 = <955000 955000 1120000>;
			opp-microvolt-speed2-pvs0-v0 = <1100000 1100000 1120000>;
			opp-microvolt-speed2-pvs1-v0 = <1075000 1075000 1120000>;
			opp-microvolt-speed2-pvs2-v0 = <1050000 1050000 1120000>;
			opp-microvolt-speed2-pvs3-v0 = <1025000 1025000 1120000>;
			opp-microvolt-speed2-pvs4-v0 = <1000000 1000000 1120000>;
			opp-microvolt-speed2-pvs5-v0 = <975000 975000 1120000>;
			opp-microvolt-speed2-pvs6-v0 = <950000 950000 1120000>;
			opp-microvolt-speed3-pvs0-v0 = <1050000 1050000 1120000>;
			opp-microvolt-speed3-pvs0-v1 = <1070000 1070000 1120000>;
			opp-microvolt-speed3-pvs1-v0 = <1025000 1025000 1120000>;
			opp-microvolt-speed3-pvs1-v1 = <1060000 1060000 1120000>;
			opp-microvolt-speed3-pvs2-v0 = <1000000 1000000 1120000>;
			opp-microvolt-speed3-pvs2-v1 = <1050000 1050000 1120000>;
			opp-microvolt-speed3-pvs3-v0 = <975000 975000 1120000>;
			opp-microvolt-speed3-pvs3-v1 = <1040000 1040000 1120000>;
			opp-microvolt-speed3-pvs4-v0 = <950000 950000 1120000>;
			opp-microvolt-speed3-pvs4-v1 = <1030000 1030000 1120000>;
			opp-microvolt-speed3-pvs5-v0 = <925000 925000 1120000>;
			opp-microvolt-speed3-pvs5-v1 = <1020000 1020000 1120000>;
			opp-microvolt-speed3-pvs6-v0 = <900000 900000 1120000>;
			opp-microvolt-speed3-pvs6-v1 = <1010000 1010000 1120000>;
			opp-microvolt-speed3-pvs7-v1 = <1000000 1000000 1120000>;
			opp-microvolt-speed3-pvs8-v1 = <990000 990000 1120000>;
			opp-microvolt-speed3-pvs9-v1 = <980000 980000 1120000>;
			opp-microvolt-speed3-pvs10-v1 = <970000 970000 1120000>;
			opp-microvolt-speed3-pvs11-v1 = <960000 960000 1120000>;
			opp-microvolt-speed3-pvs12-v1 = <950000 950000 1120000>;
			opp-microvolt-speed3-pvs13-v1 = <940000 940000 1120000>;
			opp-microvolt-speed3-pvs14-v1 = <930000 930000 1120000>;
			opp-microvolt-speed3-pvs15-v1 = <920000 920000 1120000>;
			status = "disabled";	/* above the safe rail cap */
		};

		opp-2188800000 {
			opp-hz = /bits/ 64 <2188800000>;
			opp-supported-hw = <0xa>;
			opp-microvolt-speed1-pvs0-v0 = <1060000 1060000 1120000>;
			opp-microvolt-speed1-pvs0-v1 = <1105000 1105000 1120000>;
			opp-microvolt-speed1-pvs1-v0 = <1035000 1035000 1120000>;
			opp-microvolt-speed1-pvs1-v1 = <1095000 1095000 1120000>;
			opp-microvolt-speed1-pvs2-v0 = <1010000 1010000 1120000>;
			opp-microvolt-speed1-pvs2-v1 = <1085000 1085000 1120000>;
			opp-microvolt-speed1-pvs3-v0 = <985000 985000 1120000>;
			opp-microvolt-speed1-pvs3-v1 = <1075000 1075000 1120000>;
			opp-microvolt-speed1-pvs4-v0 = <960000 960000 1120000>;
			opp-microvolt-speed1-pvs4-v1 = <1065000 1065000 1120000>;
			opp-microvolt-speed1-pvs5-v0 = <940000 940000 1120000>;
			opp-microvolt-speed1-pvs5-v1 = <1055000 1055000 1120000>;
			opp-microvolt-speed1-pvs6-v0 = <915000 915000 1120000>;
			opp-microvolt-speed1-pvs6-v1 = <1045000 1045000 1120000>;
			opp-microvolt-speed1-pvs7-v1 = <1035000 1035000 1120000>;
			opp-microvolt-speed1-pvs8-v1 = <1025000 1025000 1120000>;
			opp-microvolt-speed1-pvs9-v1 = <1015000 1015000 1120000>;
			opp-microvolt-speed1-pvs10-v1 = <1005000 1005000 1120000>;
			opp-microvolt-speed1-pvs11-v1 = <995000 995000 1120000>;
			opp-microvolt-speed1-pvs12-v1 = <985000 985000 1120000>;
			opp-microvolt-speed1-pvs13-v1 = <975000 975000 1120000>;
			opp-microvolt-speed1-pvs14-v1 = <965000 965000 1120000>;
			opp-microvolt-speed1-pvs15-v1 = <955000 955000 1120000>;
			opp-microvolt-speed3-pvs0-v0 = <1050000 1050000 1120000>;
			opp-microvolt-speed3-pvs0-v1 = <1070000 1070000 1120000>;
			opp-microvolt-speed3-pvs1-v0 = <1025000 1025000 1120000>;
			opp-microvolt-speed3-pvs1-v1 = <1060000 1060000 1120000>;
			opp-microvolt-speed3-pvs2-v0 = <1000000 1000000 1120000>;
			opp-microvolt-speed3-pvs2-v1 = <1050000 1050000 1120000>;
			opp-microvolt-speed3-pvs3-v0 = <975000 975000 1120000>;
			opp-microvolt-speed3-pvs3-v1 = <1040000 1040000 1120000>;
			opp-microvolt-speed3-pvs4-v0 = <950000 950000 1120000>;
			opp-microvolt-speed3-pvs4-v1 = <1030000 1030000 1120000>;
			opp-microvolt-speed3-pvs5-v0 = <925000 925000 1120000>;
			opp-microvolt-speed3-pvs5-v1 = <1020000 1020000 1120000>;
			opp-microvolt-speed3-pvs6-v0 = <900000 900000 1120000>;
			opp-microvolt-speed3-pvs6-v1 = <1010000 1010000 1120000>;
			opp-microvolt-speed3-pvs7-v1 = <1000000 1000000 1120000>;
			opp-microvolt-speed3-pvs8-v1 = <990000 990000 1120000>;
			opp-microvolt-speed3-pvs9-v1 = <980000 980000 1120000>;
			opp-microvolt-speed3-pvs10-v1 = <970000 970000 1120000>;
			opp-microvolt-speed3-pvs11-v1 = <960000 960000 1120000>;
			opp-microvolt-speed3-pvs12-v1 = <950000 950000 1120000>;
			opp-microvolt-speed3-pvs13-v1 = <940000 940000 1120000>;
			opp-microvolt-speed3-pvs14-v1 = <930000 930000 1120000>;
			opp-microvolt-speed3-pvs15-v1 = <920000 920000 1120000>;
			status = "disabled";	/* above the safe rail cap */
		};

		opp-2265600000 {
			opp-hz = /bits/ 64 <2265600000>;
			opp-supported-hw = <0xa>;
			opp-microvolt-speed1-pvs0-v0 = <1075000 1075000 1120000>;
			opp-microvolt-speed1-pvs0-v1 = <1120000 1120000 1120000>;
			opp-microvolt-speed1-pvs1-v0 = <1050000 1050000 1120000>;
			opp-microvolt-speed1-pvs1-v1 = <1110000 1110000 1120000>;
			opp-microvolt-speed1-pvs2-v0 = <1025000 1025000 1120000>;
			opp-microvolt-speed1-pvs2-v1 = <1100000 1100000 1120000>;
			opp-microvolt-speed1-pvs3-v0 = <1000000 1000000 1120000>;
			opp-microvolt-speed1-pvs3-v1 = <1090000 1090000 1120000>;
			opp-microvolt-speed1-pvs4-v0 = <975000 975000 1120000>;
			opp-microvolt-speed1-pvs4-v1 = <1080000 1080000 1120000>;
			opp-microvolt-speed1-pvs5-v0 = <950000 950000 1120000>;
			opp-microvolt-speed1-pvs5-v1 = <1070000 1070000 1120000>;
			opp-microvolt-speed1-pvs6-v0 = <925000 925000 1120000>;
			opp-microvolt-speed1-pvs6-v1 = <1060000 1060000 1120000>;
			opp-microvolt-speed1-pvs7-v1 = <1050000 1050000 1120000>;
			opp-microvolt-speed1-pvs8-v1 = <1040000 1040000 1120000>;
			opp-microvolt-speed1-pvs9-v1 = <1030000 1030000 1120000>;
			opp-microvolt-speed1-pvs10-v1 = <1020000 1020000 1120000>;
			opp-microvolt-speed1-pvs11-v1 = <1010000 1010000 1120000>;
			opp-microvolt-speed1-pvs12-v1 = <1000000 1000000 1120000>;
			opp-microvolt-speed1-pvs13-v1 = <990000 990000 1120000>;
			opp-microvolt-speed1-pvs14-v1 = <980000 980000 1120000>;
			opp-microvolt-speed1-pvs15-v1 = <970000 970000 1120000>;
			opp-microvolt-speed3-pvs0-v0 = <1065000 1065000 1120000>;
			opp-microvolt-speed3-pvs0-v1 = <1085000 1085000 1120000>;
			opp-microvolt-speed3-pvs1-v0 = <1040000 1040000 1120000>;
			opp-microvolt-speed3-pvs1-v1 = <1075000 1075000 1120000>;
			opp-microvolt-speed3-pvs2-v0 = <1015000 1015000 1120000>;
			opp-microvolt-speed3-pvs2-v1 = <1065000 1065000 1120000>;
			opp-microvolt-speed3-pvs3-v0 = <990000 990000 1120000>;
			opp-microvolt-speed3-pvs3-v1 = <1055000 1055000 1120000>;
			opp-microvolt-speed3-pvs4-v0 = <965000 965000 1120000>;
			opp-microvolt-speed3-pvs4-v1 = <1045000 1045000 1120000>;
			opp-microvolt-speed3-pvs5-v0 = <940000 940000 1120000>;
			opp-microvolt-speed3-pvs5-v1 = <1035000 1035000 1120000>;
			opp-microvolt-speed3-pvs6-v0 = <915000 915000 1120000>;
			opp-microvolt-speed3-pvs6-v1 = <1025000 1025000 1120000>;
			opp-microvolt-speed3-pvs7-v1 = <1015000 1015000 1120000>;
			opp-microvolt-speed3-pvs8-v1 = <1005000 1005000 1120000>;
			opp-microvolt-speed3-pvs9-v1 = <995000 995000 1120000>;
			opp-microvolt-speed3-pvs10-v1 = <985000 985000 1120000>;
			opp-microvolt-speed3-pvs11-v1 = <975000 975000 1120000>;
			opp-microvolt-speed3-pvs12-v1 = <965000 965000 1120000>;
			opp-microvolt-speed3-pvs13-v1 = <955000 955000 1120000>;
			opp-microvolt-speed3-pvs14-v1 = <945000 945000 1120000>;
			opp-microvolt-speed3-pvs15-v1 = <935000 935000 1120000>;
			status = "disabled";	/* above the safe rail cap */
		};

		opp-2342400000 {
			opp-hz = /bits/ 64 <2342400000>;
			opp-supported-hw = <0x8>;
			opp-microvolt-speed3-pvs0-v0 = <1080000 1080000 1120000>;
			opp-microvolt-speed3-pvs0-v1 = <1100000 1100000 1120000>;
			opp-microvolt-speed3-pvs1-v0 = <1055000 1055000 1120000>;
			opp-microvolt-speed3-pvs1-v1 = <1090000 1090000 1120000>;
			opp-microvolt-speed3-pvs2-v0 = <1030000 1030000 1120000>;
			opp-microvolt-speed3-pvs2-v1 = <1080000 1080000 1120000>;
			opp-microvolt-speed3-pvs3-v0 = <1005000 1005000 1120000>;
			opp-microvolt-speed3-pvs3-v1 = <1070000 1070000 1120000>;
			opp-microvolt-speed3-pvs4-v0 = <980000 980000 1120000>;
			opp-microvolt-speed3-pvs4-v1 = <1060000 1060000 1120000>;
			opp-microvolt-speed3-pvs5-v0 = <955000 955000 1120000>;
			opp-microvolt-speed3-pvs5-v1 = <1050000 1050000 1120000>;
			opp-microvolt-speed3-pvs6-v0 = <930000 930000 1120000>;
			opp-microvolt-speed3-pvs6-v1 = <1040000 1040000 1120000>;
			opp-microvolt-speed3-pvs7-v1 = <1030000 1030000 1120000>;
			opp-microvolt-speed3-pvs8-v1 = <1020000 1020000 1120000>;
			opp-microvolt-speed3-pvs9-v1 = <1010000 1010000 1120000>;
			opp-microvolt-speed3-pvs10-v1 = <1000000 1000000 1120000>;
			opp-microvolt-speed3-pvs11-v1 = <990000 990000 1120000>;
			opp-microvolt-speed3-pvs12-v1 = <980000 980000 1120000>;
			opp-microvolt-speed3-pvs13-v1 = <970000 970000 1120000>;
			opp-microvolt-speed3-pvs14-v1 = <960000 960000 1120000>;
			opp-microvolt-speed3-pvs15-v1 = <950000 950000 1120000>;
			status = "disabled";	/* above the safe rail cap */
		};

		opp-2419200000 {
			opp-hz = /bits/ 64 <2419200000>;
			opp-supported-hw = <0x8>;
			opp-microvolt-speed3-pvs0-v0 = <1095000 1095000 1120000>;
			opp-microvolt-speed3-pvs0-v1 = <1115000 1115000 1120000>;
			opp-microvolt-speed3-pvs1-v0 = <1070000 1070000 1120000>;
			opp-microvolt-speed3-pvs1-v1 = <1105000 1105000 1120000>;
			opp-microvolt-speed3-pvs2-v0 = <1045000 1045000 1120000>;
			opp-microvolt-speed3-pvs2-v1 = <1095000 1095000 1120000>;
			opp-microvolt-speed3-pvs3-v0 = <1020000 1020000 1120000>;
			opp-microvolt-speed3-pvs3-v1 = <1085000 1085000 1120000>;
			opp-microvolt-speed3-pvs4-v0 = <995000 995000 1120000>;
			opp-microvolt-speed3-pvs4-v1 = <1075000 1075000 1120000>;
			opp-microvolt-speed3-pvs5-v0 = <970000 970000 1120000>;
			opp-microvolt-speed3-pvs5-v1 = <1065000 1065000 1120000>;
			opp-microvolt-speed3-pvs6-v0 = <945000 945000 1120000>;
			opp-microvolt-speed3-pvs6-v1 = <1055000 1055000 1120000>;
			opp-microvolt-speed3-pvs7-v1 = <1045000 1045000 1120000>;
			opp-microvolt-speed3-pvs8-v1 = <1035000 1035000 1120000>;
			opp-microvolt-speed3-pvs9-v1 = <1025000 1025000 1120000>;
			opp-microvolt-speed3-pvs10-v1 = <1015000 1015000 1120000>;
			opp-microvolt-speed3-pvs11-v1 = <1005000 1005000 1120000>;
			opp-microvolt-speed3-pvs12-v1 = <995000 995000 1120000>;
			opp-microvolt-speed3-pvs13-v1 = <985000 985000 1120000>;
			opp-microvolt-speed3-pvs14-v1 = <975000 975000 1120000>;
			opp-microvolt-speed3-pvs15-v1 = <965000 965000 1120000>;
			status = "disabled";	/* above the safe rail cap */
		};

		opp-2457600000 {
			opp-hz = /bits/ 64 <2457600000>;
			opp-supported-hw = <0x8>;
			opp-microvolt-speed3-pvs0-v0 = <1100000 1100000 1120000>;
			opp-microvolt-speed3-pvs0-v1 = <1120000 1120000 1120000>;
			opp-microvolt-speed3-pvs1-v0 = <1075000 1075000 1120000>;
			opp-microvolt-speed3-pvs1-v1 = <1110000 1110000 1120000>;
			opp-microvolt-speed3-pvs2-v0 = <1050000 1050000 1120000>;
			opp-microvolt-speed3-pvs2-v1 = <1100000 1100000 1120000>;
			opp-microvolt-speed3-pvs3-v0 = <1025000 1025000 1120000>;
			opp-microvolt-speed3-pvs3-v1 = <1090000 1090000 1120000>;
			opp-microvolt-speed3-pvs4-v0 = <1000000 1000000 1120000>;
			opp-microvolt-speed3-pvs4-v1 = <1080000 1080000 1120000>;
			opp-microvolt-speed3-pvs5-v0 = <975000 975000 1120000>;
			opp-microvolt-speed3-pvs5-v1 = <1070000 1070000 1120000>;
			opp-microvolt-speed3-pvs6-v0 = <950000 950000 1120000>;
			opp-microvolt-speed3-pvs6-v1 = <1060000 1060000 1120000>;
			opp-microvolt-speed3-pvs7-v1 = <1050000 1050000 1120000>;
			opp-microvolt-speed3-pvs8-v1 = <1040000 1040000 1120000>;
			opp-microvolt-speed3-pvs9-v1 = <1030000 1030000 1120000>;
			opp-microvolt-speed3-pvs10-v1 = <1020000 1020000 1120000>;
			opp-microvolt-speed3-pvs11-v1 = <1010000 1010000 1120000>;
			opp-microvolt-speed3-pvs12-v1 = <1000000 1000000 1120000>;
			opp-microvolt-speed3-pvs13-v1 = <990000 990000 1120000>;
			opp-microvolt-speed3-pvs14-v1 = <980000 980000 1120000>;
			opp-microvolt-speed3-pvs15-v1 = <970000 970000 1120000>;
			status = "disabled";	/* above the safe rail cap */
		};

	};
};
